VERSION " "
NS_ :

BS_:

BU_: ACU BDCM EPS BMS MCU VCU1 CDU TBOX EHB ESC Tester IHU PLG PTC EACP CLM ICU TAP ALM
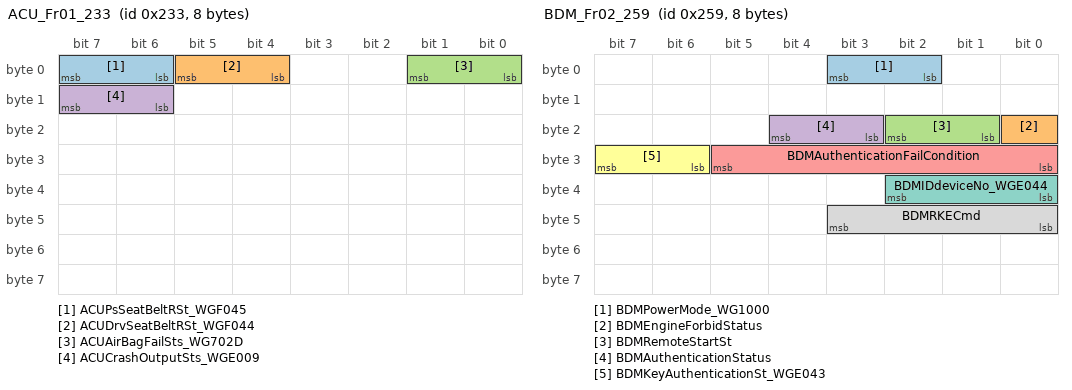
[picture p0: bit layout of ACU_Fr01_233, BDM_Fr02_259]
BO_ 563 ACU_Fr01_233: 8 ACU
 SG_ ACUPsSeatBeltRSt_WGF045 : 7|2@0+(1,0)[0|3] "" Vector__XXX
 SG_ ACUDrvSeatBeltRSt_WGF044 : 5|2@0+(1,0)[0|3] "" Vector__XXX
 SG_ ACUAirBagFailSts_WG702D : 1|2@0+(1,0)[0|3] "" Vector__XXX
 SG_ ACUCrashOutputSts_WGE009 : 15|2@0+(1,0)[0|3] "" Vector__XXX
BO_ 825 BDM_Fr01_339: 8 BDCM
 SG_ BDMAlarmMode_WG704C : 2|3@0+(1,0)[0|7] "" Vector__XXX
 SG_ BDMBackDoorAjar_WGC00E : 7|3@0+(1,0)[0|7] "" Vector__XXX
 SG_ BDMDriverDoorAjar_WGC00A : 9|2@0+(1,0)[0|3] "" Vector__XXX
 SG_ BDMPassDoorAjar_WGC00B : 11|2@0+(1,0)[0|3] "" Vector__XXX
 SG_ BDMRearDriverDoorAjar_WGC00C : 13|2@0+(1,0)[0|3] "" Vector__XXX
 SG_ BDMRearPassDoorAjar_WGC00D : 15|2@0+(1,0)[0|3] "" Vector__XXX
 SG_ BDMPositionLampSt_WGC003 : 16|1@0+(1,0)[0|1] "" Vector__XXX
 SG_ BDMBacklightStatus : 17|1@0+(1,0)[0|1] "" Vector__XXX
 SG_ BDMLowBeamSt_WGC009 : 18|1@0+(1,0)[0|1] "" Vector__XXX
 SG_ BDMLeftTurnLightSt_WGC006 : 19|1@0+(1,0)[0|1] "" Vector__XXX
 SG_ BDMRightTurnLightSt_WGC007 : 20|1@0+(1,0)[0|1] "" Vector__XXX
 SG_ BDMRearFogLampSt_WGC002 : 21|1@0+(1,0)[0|1] "" Vector__XXX
 SG_ BDMFrontFogLampSt : 22|1@0+(1,0)[0|1] "" Vector__XXX
 SG_ BDMDRLSt : 23|1@0+(1,0)[0|1] "" Vector__XXX
 SG_ BDMHighBeamSt_WGC008 : 24|1@0+(1,0)[0|1] "" Vector__XXX
 SG_ BDMHazardLampSt_WGF015 : 25|1@0+(1,0)[0|1] "" Vector__XXX
 SG_ BDMFrontWiperSt : 34|3@0+(1,0)[0|7] "" Vector__XXX
 SG_ BDMDoorLockSts_WGF000 : 38|1@0+(1,0)[0|1] "" Vector__XXX
 SG_ BDMRearDefrostSts : 39|1@0+(1,0)[0|1] "" Vector__XXX
 SG_ BDMTrunkLockSts_WGF004 : 43|1@0+(1,0)[0|1] "" Vector__XXX
BO_ 601 BDM_Fr02_259: 8 BDCM
 SG_ BDMPowerMode_WG1000 : 3|2@0+(1,0)[0|3] "" Vector__XXX
 SG_ BDMEngineForbidStatus : 16|1@0+(1,0)[0|1] "" Vector__XXX
 SG_ BDMRemoteStartSt : 18|2@0+(1,0)[0|3] "" Vector__XXX
 SG_ BDMAuthenticationStatus : 20|2@0+(1,0)[0|3] "" Vector__XXX
 SG_ BDMAuthenticationFailCondition : 29|6@0+(1,0)[0|63] "" Vector__XXX
 SG_ BDMKeyAuthenticationSt_WGE043 : 31|2@0+(1,0)[0|3] "" Vector__XXX
 SG_ BDMIDdeviceNo_WGE044 : 34|3@0+(1,0)[0|7] "" Vector__XXX
 SG_ BDMRKECmd : 43|4@0+(1,0)[0|15] "" Vector__XXX
BO_ 618 BDM_Fr03_26A: 8 BDCM
 SG_ BDMDoorHandleSensorFailureInd : 1|1@0+(1,0)[0|1] "" Vector__XXX
 SG_ BDMBrakeLightSts_WGF01B : 2|1@0+(1,0)[0|1] "" Vector__XXX
 SG_ BDMKeyNotFindIndication : 10|1@0+(1,0)[0|1] "" Vector__XXX
 SG_ BDMKeyLowBatteryIndication : 11|1@0+(1,0)[0|1] "" Vector__XXX
 SG_ BDMKeyInIndication : 12|1@0+(1,0)[0|1] "" Vector__XXX
 SG_ BDMDepressBrakePedalIndication : 14|1@0+(1,0)[0|1] "" Vector__XXX
 SG_ BDMShiftGearToPNIndication : 15|1@0+(1,0)[0|1] "" Vector__XXX
 SG_ BDMShiftGearToPIndication : 16|1@0+(1,0)[0|1] "" Vector__XXX
 SG_ BDMBackupStartIndication : 17|1@0+(1,0)[0|1] "" Vector__XXX
 SG_ RearFogLampFailedSts : 42|1@0+(1,0)[0|1] "" Vector__XXX
 SG_ SSBFailedSts : 45|1@0+(1,0)[0|1] "" Vector__XXX
 SG_ CHMSLFailedSts : 21|1@0+(1,0)[0|1] "" Vector__XXX
 SG_ StopLampFailedSts_WG7049 : 22|1@0+(1,0)[0|1] "" Vector__XXX
 SG_ SRMSunroofPosition : 34|3@0+(1,0)[0|7] "" Vector__XXX
 SG_ SRMSunshadePosition : 47|2@0+(1,0)[0|3] "" Vector__XXX
 SG_ DriverHeatingStatus : 50|3@0+(1,0)[0|7] "" Vector__XXX
 SG_ PassengerHeatingStatus : 53|3@0+(1,0)[0|7] "" Vector__XXX
 SG_ SHMLHFailure : 57|1@0+(1,0)[0|1] "" Vector__XXX
 SG_ SHMRHFailure : 56|1@0+(1,0)[0|1] "" Vector__XXX
BO_ 906 BDM_Fr04_38A: 8 BDCM
 SG_ BDMRtyreStatus : 0|1@0+(1,0)[0|1] "" Vector__XXX
 SG_ BDMRLTyreLearntSt : 1|1@0+(1,0)[0|1] "" Vector__XXX
 SG_ BDMRLTyrePressureWarn_WG500F : 3|2@0+(1,0)[0|3] "" Vector__XXX
 SG_ BDMRLTyreTemperatureWarn_WG5011 : 4|1@0+(1,0)[0|1] "" Vector__XXX
 SG_ BDMRLTyreQucikLeak : 5|1@0+(1,0)[0|1] "" Vector__XXX
 SG_ BDMRLTyreSensorFailure : 6|1@0+(1,0)[0|1] "" Vector__XXX
 SG_ BDMRLTyreLowBattery_WG5012 : 7|1@0+(1,0)[0|1] "" Vector__XXX
 SG_ BDMRLTyrePressure_WGF024 : 15|8@0+(1.373,100)[100|488.742] "" Vector__XXX
 SG_ BDMRLTyreTemperature_WGF023 : 23|8@0+(1,-60)[-60|194] "" Vector__XXX
 SG_ BDMRRTyreLearntSt : 25|1@0+(1,0)[0|1] "" Vector__XXX
 SG_ BDMRRTyrePressureWarn_WG5015 : 27|2@0+(1,0)[0|3] "" Vector__XXX
 SG_ BDMRRTyreTemperatureWarn_WG5017 : 28|1@0+(1,0)[0|1] "" Vector__XXX
 SG_ BDMRRTyreQucikLeak : 29|1@0+(1,0)[0|1] "" Vector__XXX
 SG_ BDMRRTyreSensorFailure : 30|1@0+(1,0)[0|1] "" Vector__XXX
 SG_ BDMRRTyreLowBattery_WG5018 : 31|1@0+(1,0)[0|1] "" Vector__XXX
 SG_ BDMRRTyrePressure_WGF022 : 39|8@0+(1.373,100)[100|488.742] "" Vector__XXX
 SG_ BDMRRTyreTemperature_WGF021 : 47|8@0+(1,-60)[-60|194] "" Vector__XXX
BO_ 874 BDM_Fr05_36A: 8 BDCM
 SG_ BDMFtyreStatus : 0|1@0+(1,0)[0|1] "" Vector__XXX
 SG_ BDMFLTyreLearntSt : 1|1@0+(1,0)[0|1] "" Vector__XXX
 SG_ BDMFLTyrePressureWarn_WG5003 : 3|2@0+(1,0)[0|3] "" Vector__XXX
 SG_ BDMFLTyreTemperatureWarn_WG5005 : 4|1@0+(1,0)[0|1] "" Vector__XXX
 SG_ BDMFLTyreQucikLeak : 5|1@0+(1,0)[0|1] "" Vector__XXX
 SG_ BDMFLTyreSensorFailure : 6|1@0+(1,0)[0|1] "" Vector__XXX
 SG_ BDMFLTyreLowBattery_WG5006 : 7|1@0+(1,0)[0|1] "" Vector__XXX
 SG_ BDMFLTyrePressure_WGF020 : 15|8@0+(1.373,100)[100|488.742] "" Vector__XXX
 SG_ BDMFLTyreTemperature_WGF01F : 23|8@0+(1,-60)[-60|194] "" Vector__XXX
 SG_ BDMFRTyreLearntSt : 25|1@0+(1,0)[0|1] "" Vector__XXX
 SG_ BDMFRTyrePressureWarn_WG5009 : 27|2@0+(1,0)[0|3] "" Vector__XXX
 SG_ BDMFRTyreTemperatureWarn_WG500B : 28|1@0+(1,0)[0|1] "" Vector__XXX
 SG_ BDMFRTyreQucikLeak : 29|1@0+(1,0)[0|1] "" Vector__XXX
 SG_ BDMFRTyreSensorFailure : 30|1@0+(1,0)[0|1] "" Vector__XXX
 SG_ BDMFRTyreLowBattery_WG500C : 31|1@0+(1,0)[0|1] "" Vector__XXX
 SG_ BDMFRTyrePressure_WGF01E : 39|8@0+(1.373,100)[100|488.742] "" Vector__XXX
 SG_ BDMFRTyreTemperature_WGF01D : 47|8@0+(1,-60)[-60|194] "" Vector__XXX
 SG_ BDMSystemFailure_WG704B : 55|2@0+(1,0)[0|3] "" Vector__XXX
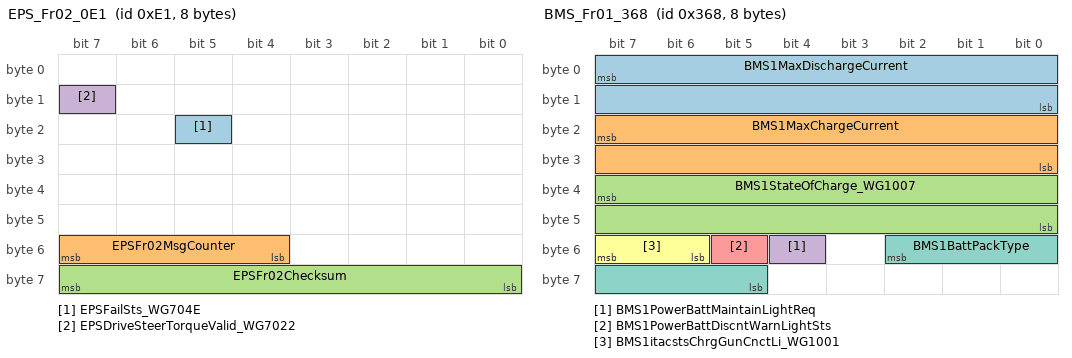
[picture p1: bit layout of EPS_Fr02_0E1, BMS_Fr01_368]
BO_ 225 EPS_Fr02_0E1: 8 EPS
 SG_ EPSFailSts_WG704E : 21|1@0+(1,0)[0|1] "" Vector__XXX
 SG_ EPSFr02MsgCounter : 55|4@0+(1,0)[0|15] "" Vector__XXX
 SG_ EPSFr02Checksum : 63|8@0+(1,0)[0|255] "" Vector__XXX
 SG_ EPSDriveSteerTorqueValid_WG7022 : 15|1@0+(1,0)[0|1] "" Vector__XXX
BO_ 481 EPS_Fr03_1E1: 8 EPS
 SG_ EPSSteeringAngleValid : 6|1@0+(1,0)[0|1] "" Vector__XXX
 SG_ EPSSteeringAngleSpd : 15|8@0+(4,0)[0|1020] "dgree/s" Vector__XXX
 SG_ EPSSteeringAngle_WGF03A : 23|16@0+(0.1,-720)[-720|720] "dgree" Vector__XXX
 SG_ EPSEleStrFailFlag_WG7021 : 3|2@0+(1,0)[0|3] "" Vector__XXX
BO_ 872 BMS_Fr01_368: 8 BMS
 SG_ BMS1MaxDischargeCurrent : 7|16@0+(0.05,-1600)[0|1024] "A" Vector__XXX
 SG_ BMS1MaxChargeCurrent : 23|16@0+(0.05,-1600)[0|1024] "A" Vector__XXX
 SG_ BMS1StateOfCharge_WG1007 : 39|16@0+(0.01,0)[0|100] "%" Vector__XXX
 SG_ BMS1PowerBattMaintainLightReq : 52|1@0+(1,0)[0|1] "" Vector__XXX
 SG_ BMS1PowerBattDiscntWarnLightSts : 53|1@0+(1,0)[0|1] "" Vector__XXX
 SG_ BMS1itacstsChrgGunCnctLi_WG1001 : 55|2@0+(1,0)[0|3] "" Vector__XXX
 SG_ BMS1BattPackType : 50|6@0+(1,0)[0|63] "" Vector__XXX
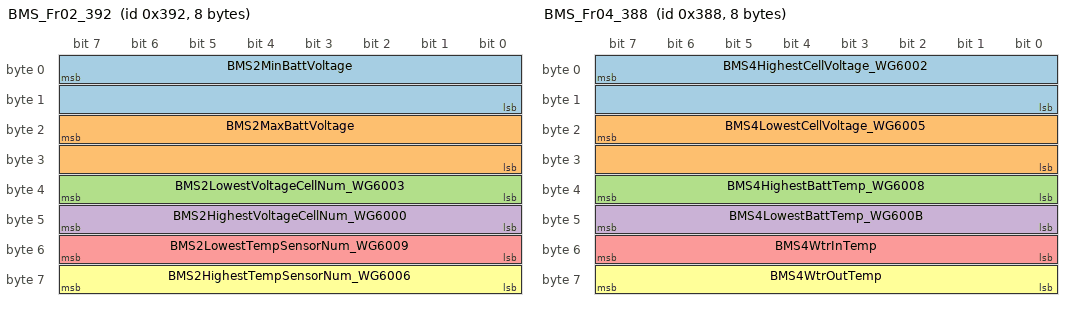
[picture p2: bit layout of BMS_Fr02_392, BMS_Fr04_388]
BO_ 914 BMS_Fr02_392: 8 BMS
 SG_ BMS2MinBattVoltage : 7|16@0+(0.05,0)[0|1000] "V" Vector__XXX
 SG_ BMS2MaxBattVoltage : 23|16@0+(0.05,0)[0|1000] "V" Vector__XXX
 SG_ BMS2LowestVoltageCellNum_WG6003 : 39|8@0+(1,0)[0|200] "" Vector__XXX
 SG_ BMS2HighestVoltageCellNum_WG6000 : 47|8@0+(1,0)[0|200] "" Vector__XXX
 SG_ BMS2LowestTempSensorNum_WG6009 : 55|8@0+(1,0)[0|200] "" Vector__XXX
 SG_ BMS2HighestTempSensorNum_WG6006 : 63|8@0+(1,0)[0|200] "" Vector__XXX
BO_ 858 BMS_Fr03_35A: 8 BMS
 SG_ BMS3BatteryCurrent_WG1006 : 7|16@0+(0.05,-1600)[-600|600] "A" Vector__XXX
 SG_ BMS3BatteryVoltage_WG1005 : 23|16@0+(0.05,0)[0|1000] "V" Vector__XXX
 SG_ BMS3AverageBattTemp : 55|8@0+(1,-40)[-40|125] "℃" Vector__XXX
 SG_ BMS3StateOfHealth : 63|8@0+(1,0)[0|100] "%" Vector__XXX
BO_ 904 BMS_Fr04_388: 8 BMS
 SG_ BMS4HighestCellVoltage_WG6002 : 7|16@0+(1,0)[0|5000] "mv" Vector__XXX
 SG_ BMS4LowestCellVoltage_WG6005 : 23|16@0+(1,0)[0|5000] "mv" Vector__XXX
 SG_ BMS4HighestBattTemp_WG6008 : 39|8@0+(1,-40)[-40|125] "℃" Vector__XXX
 SG_ BMS4LowestBattTemp_WG600B : 47|8@0+(1,-40)[-40|125] "℃" Vector__XXX
 SG_ BMS4WtrInTemp : 55|8@0+(1,-40)[-40|125] "℃" Vector__XXX
 SG_ BMS4WtrOutTemp : 63|8@0+(1,-40)[-40|125] "℃" Vector__XXX
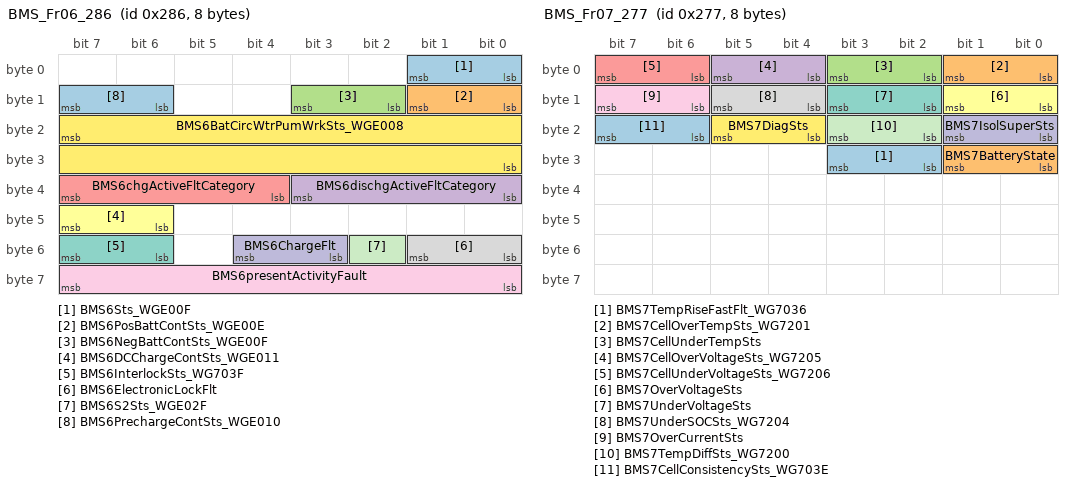
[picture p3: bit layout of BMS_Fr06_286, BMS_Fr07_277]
BO_ 646 BMS_Fr06_286: 8 BMS
 SG_ BMS6Sts_WGE00F : 1|2@0+(1,0)[0|3] "" Vector__XXX
 SG_ BMS6PosBattContSts_WGE00E : 9|2@0+(1,0)[0|3] "" Vector__XXX
 SG_ BMS6NegBattContSts_WGE00F : 11|2@0+(1,0)[0|3] "" Vector__XXX
 SG_ BMS6dischgActiveFltCategory : 35|4@0+(1,0)[0|15] "" Vector__XXX
 SG_ BMS6chgActiveFltCategory : 39|4@0+(1,0)[0|15] "" Vector__XXX
 SG_ BMS6DCChargeContSts_WGE011 : 47|2@0+(1,0)[0|3] "" Vector__XXX
 SG_ BMS6InterlockSts_WG703F : 55|2@0+(1,0)[0|3] "" Vector__XXX
 SG_ BMS6ElectronicLockFlt : 49|2@0+(1,0)[0|3] "" Vector__XXX
 SG_ BMS6presentActivityFault : 63|8@0+(1,0)[0|128] "" Vector__XXX
 SG_ BMS6ChargeFlt : 52|2@0+(1,0)[0|3] "" Vector__XXX
 SG_ BMS6S2Sts_WGE02F : 50|1@0+(1,0)[0|1] "" Vector__XXX
 SG_ BMS6BatCircWtrPumWrkSts_WGE008 : 23|16@0+(0.1,0)[0|100] "%" Vector__XXX
 SG_ BMS6PrechargeContSts_WGE010 : 15|2@0+(1,0)[0|3] "" Vector__XXX
BO_ 631 BMS_Fr07_277: 8 BMS
 SG_ BMS7TempRiseFastFlt_WG7036 : 27|2@0+(1,0)[0|3] "" Vector__XXX
 SG_ BMS7CellOverTempSts_WG7201 : 1|2@0+(1,0)[0|3] "" Vector__XXX
 SG_ BMS7CellUnderTempSts : 3|2@0+(1,0)[0|3] "" Vector__XXX
 SG_ BMS7CellOverVoltageSts_WG7205 : 5|2@0+(1,0)[0|3] "" Vector__XXX
 SG_ BMS7CellUnderVoltageSts_WG7206 : 7|2@0+(1,0)[0|3] "" Vector__XXX
 SG_ BMS7OverVoltageSts : 9|2@0+(1,0)[0|3] "" Vector__XXX
 SG_ BMS7UnderVoltageSts : 11|2@0+(1,0)[0|3] "" Vector__XXX
 SG_ BMS7UnderSOCSts_WG7204 : 13|2@0+(1,0)[0|3] "" Vector__XXX
 SG_ BMS7OverCurrentSts : 15|2@0+(1,0)[0|3] "" Vector__XXX
 SG_ BMS7IsolSuperSts : 17|2@0+(1,0)[0|3] "" Vector__XXX
 SG_ BMS7TempDiffSts_WG7200 : 19|2@0+(1,0)[0|3] "" Vector__XXX
 SG_ BMS7DiagSts : 21|2@0+(1,0)[0|3] "" Vector__XXX
 SG_ BMS7CellConsistencySts_WG703E : 23|2@0+(1,0)[0|3] "" Vector__XXX
 SG_ BMS7BatteryState : 25|2@0+(1,0)[0|3] "" Vector__XXX
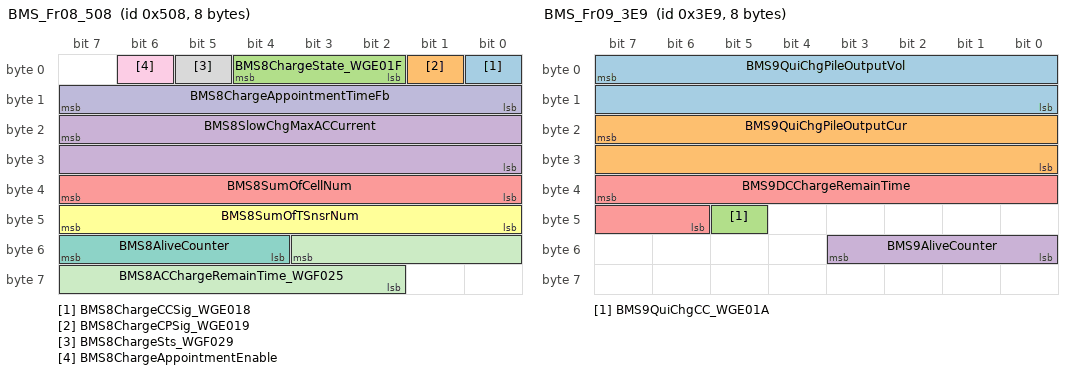
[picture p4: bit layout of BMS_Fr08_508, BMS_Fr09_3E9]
BO_ 1288 BMS_Fr08_508: 8 BMS
 SG_ BMS8ChargeCCSig_WGE018 : 0|1@0+(1,0)[0|1] "" Vector__XXX
 SG_ BMS8ChargeCPSig_WGE019 : 1|1@0+(1,0)[0|1] "" Vector__XXX
 SG_ BMS8ChargeState_WGE01F : 4|3@0+(1,0)[0|7] "" Vector__XXX
 SG_ BMS8SlowChgMaxACCurrent : 23|16@0+(0.05,-1600)[0|600] "A" Vector__XXX
 SG_ BMS8SumOfCellNum : 39|8@0+(1,0)[0|254] "" Vector__XXX
 SG_ BMS8SumOfTSnsrNum : 47|8@0+(1,0)[0|254] "" Vector__XXX
 SG_ BMS8AliveCounter : 55|4@0+(1,0)[0|15] "" Vector__XXX
 SG_ BMS8ChargeSts_WGF029 : 5|1@0+(1,0)[0|1] "" Vector__XXX
 SG_ BMS8ChargeAppointmentEnable : 6|1@0+(1,0)[0|1] "" Vector__XXX
 SG_ BMS8ChargeAppointmentTimeFb : 15|8@0+(10,0)[0|1440] "min" Vector__XXX
 SG_ BMS8ACChargeRemainTime_WGF025 : 51|10@0+(1,0)[0|1023] "min" Vector__XXX
BO_ 1001 BMS_Fr09_3E9: 8 BMS
 SG_ BMS9QuiChgPileOutputVol : 7|16@0+(0.05,0)[0|1000] "V" Vector__XXX
 SG_ BMS9QuiChgPileOutputCur : 23|16@0+(0.05,-1600)[0|600] "A" Vector__XXX
 SG_ BMS9QuiChgCC_WGE01A : 45|1@0+(1,0)[0|1] "" Vector__XXX
 SG_ BMS9AliveCounter : 51|4@0+(1,0)[0|15] "" Vector__XXX
 SG_ BMS9DCChargeRemainTime : 39|10@0+(1,0)[0|1023] "min" Vector__XXX
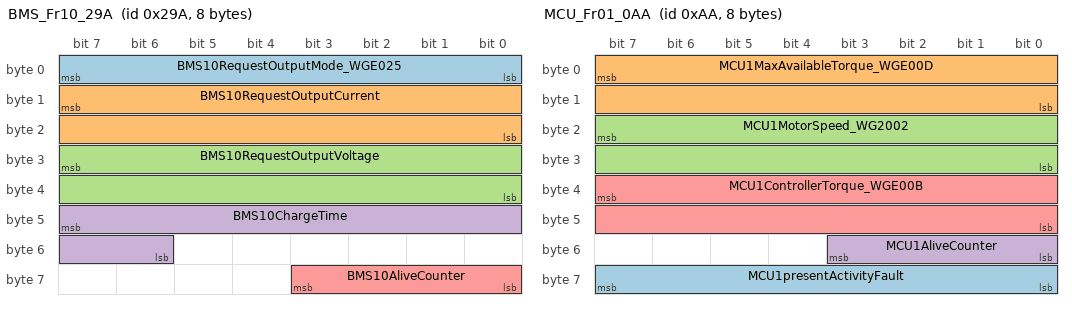
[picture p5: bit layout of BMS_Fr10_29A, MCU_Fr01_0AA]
BO_ 666 BMS_Fr10_29A: 8 BMS
 SG_ BMS10RequestOutputMode_WGE025 : 7|8@0+(1,0)[0|255] "" Vector__XXX
 SG_ BMS10RequestOutputCurrent : 15|16@0+(0.05,0)[0|400] "A" Vector__XXX
 SG_ BMS10RequestOutputVoltage : 31|16@0+(0.05,0)[0|1000] "V" Vector__XXX
 SG_ BMS10ChargeTime : 47|10@0+(1,0)[0|1023] "" Vector__XXX
 SG_ BMS10AliveCounter : 59|4@0+(1,0)[0|15] "" Vector__XXX
BO_ 1291 BMS_Fr11_50B: 8 BMS
 SG_ 单体电压号_WI1 : 7|8@0+(1,0)[0|255] "" Vector__XXX
 SG_ 单体电压1_WM1I1G8000 : 15|16@0+(1,0)[0|5000] "" Vector__XXX
 SG_ 温度探针号_WI2 : 55|8@0+(1,0)[0|255] "" Vector__XXX
 SG_ 温度探针1_WM1I2G9000 : 63|8@0+(1,-40)[-40|125] "" Vector__XXX
BO_ 170 MCU_Fr01_0AA: 8 MCU
 SG_ MCU1presentActivityFault : 63|8@0+(1,0)[0|128] "" Vector__XXX
 SG_ MCU1MaxAvailableTorque_WGE00D : 7|16@0+(0.05,0)[0|1024] "Nm" Vector__XXX
 SG_ MCU1MotorSpeed_WG2002 : 23|16@0+(0.5,-16000)[-16000|16000] "Rpm" Vector__XXX
 SG_ MCU1AliveCounter : 51|4@0+(1,0)[0|15] "" Vector__XXX
 SG_ MCU1ControllerTorque_WGE00B : 39|16@0+(0.05,-1024)[-1024|1024] "Nm" Vector__XXX
BO_ 187 MCU_Fr02_0BB: 8 MCU
 SG_ MCU2FaultLevel : 2|2@0+(1,0)[0|3] "" Vector__XXX
 SG_ MCU2MotorBlockWarning : 4|1@0+(1,0)[0|1] "" Vector__XXX
 SG_ MCU22OpenProtionLockFault_WG7038 : 5|1@0+(1,0)[0|1] "" Vector__XXX
 SG_ MCU2CoolingSystemFault : 6|1@0+(1,0)[0|1] "" Vector__XXX
 SG_ MCU2SelfcheckFault : 7|1@0+(1,0)[0|1] "" Vector__XXX
 SG_ MCU2SensorCheckFault : 12|1@0+(1,0)[0|1] "" Vector__XXX
 SG_ MCU2BatteryCheckFault_WG7025 : 13|1@0+(1,0)[0|1] "" Vector__XXX
 SG_ MCU2MotorLackofPhaseFault : 14|1@0+(1,0)[0|1] "" Vector__XXX
 SG_ MCU2RDCAlignmentFault : 15|1@0+(1,0)[0|1] "" Vector__XXX
 SG_ MCU2PhaseOvercurrentFault : 32|1@0+(1,0)[0|1] "" Vector__XXX
 SG_ MCU2InverterFault_WG7037 : 33|1@0+(1,0)[0|1] "" Vector__XXX
 SG_ MCU2SensorSupplyVoltageFault : 39|1@0+(1,0)[0|1] "" Vector__XXX
 SG_ MCU2DClinkOvercurrentFault : 40|1@0+(1,0)[0|1] "" Vector__XXX
 SG_ MCU2GateDriDesaturFault_WG7027 : 41|1@0+(1,0)[0|1] "" Vector__XXX
 SG_ MCU2MotorPosSensorFault_WG7028 : 42|1@0+(1,0)[0|1] "" Vector__XXX
 SG_ MCU22DischargeOverTime : 43|1@0+(1,0)[0|1] "" Vector__XXX
 SG_ MCU22SumPhaseCurrentOverThd : 44|1@0+(1,0)[0|1] "" Vector__XXX
 SG_ MCU2MotorOvertemperatureFault : 46|2@0+(1,0)[0|3] "" Vector__XXX
 SG_ MCU22AphaseOvercurrentWarning : 47|1@0+(1,0)[0|1] "" Vector__XXX
 SG_ MCU22BphaseOvercurrentWarning : 48|1@0+(1,0)[0|1] "" Vector__XXX
 SG_ MCU2CphaseOvercurrentWarning : 49|1@0+(1,0)[0|1] "" Vector__XXX
 SG_ MCU2InverterOvertempFault_WG720F : 51|2@0+(1,0)[0|3] "" Vector__XXX
 SG_ MCU2RxCANFailed_WG7044 : 52|1@0+(1,0)[0|1] "" Vector__XXX
 SG_ MCU2LVPowerSupplyFault : 53|1@0+(1,0)[0|1] "" Vector__XXX
 SG_ MCU2HVBatteryConnectstates : 55|1@0+(1,0)[0|1] "" Vector__XXX
 SG_ MCU2VCUInverterstates : 56|1@0+(1,0)[0|1] "" Vector__XXX
 SG_ MCU2SafetyFault : 57|1@0+(1,0)[0|1] "" Vector__XXX
 SG_ MCU2ModeError : 58|1@0+(1,0)[0|1] "" Vector__XXX
 SG_ MCU2GateDriverVoltageSupplyFault : 59|1@0+(1,0)[0|1] "" Vector__XXX
 SG_ MCU2Fr02AliveCounter : 63|4@0+(1,0)[0|15] "" Vector__XXX
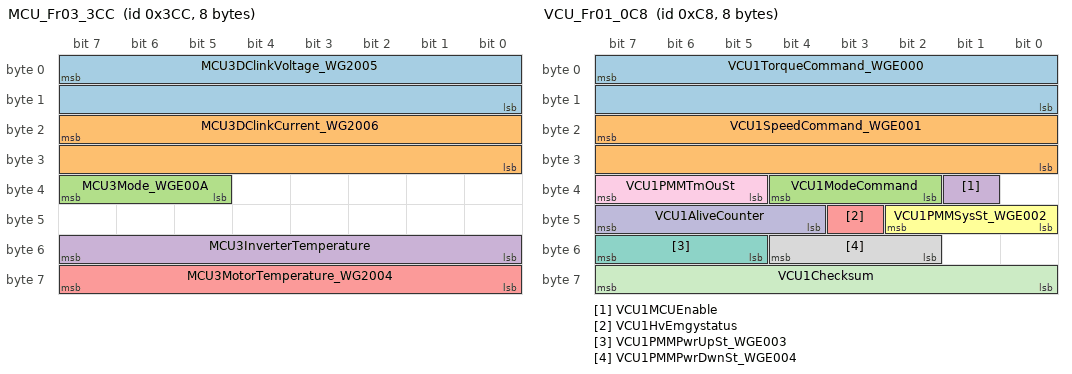
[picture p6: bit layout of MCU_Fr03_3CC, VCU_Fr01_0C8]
BO_ 972 MCU_Fr03_3CC: 8 MCU
 SG_ MCU3DClinkVoltage_WG2005 : 7|16@0+(0.05,0)[0|600] "V" Vector__XXX
 SG_ MCU3DClinkCurrent_WG2006 : 23|16@0+(0.05,-512)[-512|512] "A" Vector__XXX
 SG_ MCU3Mode_WGE00A : 39|3@0+(1,0)[0|7] "" Vector__XXX
 SG_ MCU3InverterTemperature : 55|8@0+(1,-48)[-48|206] "℃" Vector__XXX
 SG_ MCU3MotorTemperature_WG2004 : 63|8@0+(1,-48)[-48|206] "℃" Vector__XXX
BO_ 1072 MCU_Fr04_430: 8 MCU
 SG_ MCU4AlOfsNoPlaus : 0|1@0+(1,0)[0|1] "" Vector__XXX
 SG_ MCU4CanBusOff : 1|1@0+(1,0)[0|1] "" Vector__XXX
 SG_ MCU4EppPosMonShrGnd : 2|1@0+(1,0)[0|1] "" Vector__XXX
 SG_ MCU4EppPosShrGnd : 3|1@0+(1,0)[0|1] "" Vector__XXX
 SG_ MCU4IUMonOvHiRng : 4|1@0+(1,0)[0|1] "" Vector__XXX
 SG_ MCU4IUMonOvLoRng : 5|1@0+(1,0)[0|1] "" Vector__XXX
 SG_ MCU4IUOc : 6|1@0+(1,0)[0|1] "" Vector__XXX
 SG_ MCU4IUOvHiRng : 7|1@0+(1,0)[0|1] "" Vector__XXX
 SG_ MCU4IUOvLoRng : 8|1@0+(1,0)[0|1] "" Vector__XXX
 SG_ MCU4IVMonOvHiRng : 9|1@0+(1,0)[0|1] "" Vector__XXX
 SG_ MCU4IVMonOvLoRng : 10|1@0+(1,0)[0|1] "" Vector__XXX
 SG_ MCU4IVOc_WG7023 : 11|1@0+(1,0)[0|1] "" Vector__XXX
 SG_ MCU4IVOvHiRng : 12|1@0+(1,0)[0|1] "" Vector__XXX
 SG_ MCU4IVOvLoRng : 13|1@0+(1,0)[0|1] "" Vector__XXX
 SG_ MCU4IWMonOvHiRng : 14|1@0+(1,0)[0|1] "" Vector__XXX
 SG_ MCU4IWMonOvLoRng : 15|1@0+(1,0)[0|1] "" Vector__XXX
 SG_ MCU4IWOc_WG7024 : 16|1@0+(1,0)[0|1] "" Vector__XXX
 SG_ MCU4IWOvHiRng : 17|1@0+(1,0)[0|1] "" Vector__XXX
 SG_ MCU4IWOvLoRng : 18|1@0+(1,0)[0|1] "" Vector__XXX
 SG_ MCU4IphaOC_WG7029 : 19|1@0+(1,0)[0|1] "" Vector__XXX
 SG_ MCU4IphaOffCal : 20|1@0+(1,0)[0|1] "" Vector__XXX
 SG_ MCU4MosTHiRng : 21|1@0+(1,0)[0|1] "" Vector__XXX
 SG_ MCU4NFltHA : 22|1@0+(1,0)[0|1] "" Vector__XXX
 SG_ MCU4NFltHB : 23|1@0+(1,0)[0|1] "" Vector__XXX
 SG_ MCU4NFltLA : 24|1@0+(1,0)[0|1] "" Vector__XXX
 SG_ MCU4NFltLB : 25|1@0+(1,0)[0|1] "" Vector__XXX
 SG_ MCU4RslvDos : 26|1@0+(1,0)[0|1] "" Vector__XXX
 SG_ MCU4RslvLos : 27|1@0+(1,0)[0|1] "" Vector__XXX
 SG_ MCU4RslvLot : 28|1@0+(1,0)[0|1] "" Vector__XXX
 SG_ MCU4StallmotRng : 29|1@0+(1,0)[0|1] "" Vector__XXX
 SG_ MCU4HwPhaCurPosBackErr : 30|1@0+(1,0)[0|1] "" Vector__XXX
 SG_ MCU4HwPhaCurNegBackErr : 31|1@0+(1,0)[0|1] "" Vector__XXX
 SG_ MCU4TimeovRng : 32|1@0+(1,0)[0|1] "" Vector__XXX
 SG_ MCU4TSttr1OvHiLim : 33|1@0+(1,0)[0|1] "" Vector__XXX
 SG_ MCU4TSttr1OvLoLim : 34|1@0+(1,0)[0|1] "" Vector__XXX
 SG_ MCU4TSttr2OvHiLim : 35|1@0+(1,0)[0|1] "" Vector__XXX
 SG_ MCU4TSttr2OvLoLim : 36|1@0+(1,0)[0|1] "" Vector__XXX
 SG_ MCU4TUErrOff : 37|1@0+(1,0)[0|1] "" Vector__XXX
 SG_ MCU4TVErrOff : 38|1@0+(1,0)[0|1] "" Vector__XXX
 SG_ MCU4TWErrOff : 39|1@0+(1,0)[0|1] "" Vector__XXX
 SG_ MCU4tDBCTempUHiLom : 40|1@0+(1,0)[0|1] "" Vector__XXX
 SG_ MCU4tDBCTempULoLom : 41|1@0+(1,0)[0|1] "" Vector__XXX
 SG_ MCU4tDBCTempVHiLom : 42|1@0+(1,0)[0|1] "" Vector__XXX
 SG_ MCU4tDBCTempVLoLom : 43|1@0+(1,0)[0|1] "" Vector__XXX
 SG_ MCU4tDBCTempWHiLom : 44|1@0+(1,0)[0|1] "" Vector__XXX
 SG_ MCU4tDBCTempWLoLom : 45|1@0+(1,0)[0|1] "" Vector__XXX
 SG_ MCU4QtShrGnd : 46|1@0+(1,0)[0|1] "" Vector__XXX
 SG_ MCU4SttrTemp1ShrGnd : 47|1@0+(1,0)[0|1] "" Vector__XXX
 SG_ MCU4SttrTemp2ShrGnd : 48|1@0+(1,0)[0|1] "" Vector__XXX
 SG_ MCU4UMonShrGnd : 49|1@0+(1,0)[0|1] "" Vector__XXX
 SG_ MCU4VMonShrGnd : 50|1@0+(1,0)[0|1] "" Vector__XXX
 SG_ MCU4WMonShrGnd : 51|1@0+(1,0)[0|1] "" Vector__XXX
 SG_ MCU4UShrGnd : 52|1@0+(1,0)[0|1] "" Vector__XXX
 SG_ MCU4VShrGnd : 53|1@0+(1,0)[0|1] "" Vector__XXX
 SG_ MCU4WShrGnd : 54|1@0+(1,0)[0|1] "" Vector__XXX
 SG_ MCU4UKl30Ov : 55|1@0+(1,0)[0|1] "" Vector__XXX
 SG_ MCU4UKl30Unv_WG7039 : 56|1@0+(1,0)[0|1] "" Vector__XXX
 SG_ MCU4VcuRecOvTime : 57|1@0+(1,0)[0|1] "" Vector__XXX
 SG_ MCU4UdcLnkOvHiRng_WG702A : 59|2@0+(1,0)[0|3] "" Vector__XXX
 SG_ MCU4UdcLnkOvLoRng_WG702B : 61|2@0+(1,0)[0|3] "" Vector__XXX
 SG_ MCU4OverSpdDetn : 63|2@0+(1,0)[0|3] "" Vector__XXX
BO_ 200 VCU_Fr01_0C8: 8 VCU1
 SG_ VCU1TorqueCommand_WGE000 : 7|16@0+(0.05,-1024)[-1024|1024] "Nm" Vector__XXX
 SG_ VCU1SpeedCommand_WGE001 : 23|16@0+(0.5,-16000)[-16000|16000] "RPM" Vector__XXX
 SG_ VCU1ModeCommand : 36|3@0+(1,0)[0|7] "" Vector__XXX
 SG_ VCU1MCUEnable : 33|1@0+(1,0)[0|1] "" Vector__XXX
 SG_ VCU1HvEmgystatus : 43|1@0+(1,0)[0|1] "" Vector__XXX
 SG_ VCU1PMMSysSt_WGE002 : 42|3@0+(1,0)[0|7] "" Vector__XXX
 SG_ VCU1PMMPwrUpSt_WGE003 : 55|3@0+(1,0)[0|7] "" Vector__XXX
 SG_ VCU1PMMPwrDwnSt_WGE004 : 52|3@0+(1,0)[0|7] "" Vector__XXX
 SG_ VCU1PMMTmOuSt : 39|3@0+(1,0)[0|7] "" Vector__XXX
 SG_ VCU1AliveCounter : 47|4@0+(1,0)[0|15] "" Vector__XXX
 SG_ VCU1Checksum : 63|8@0+(1,0)[0|255] "" Vector__XXX
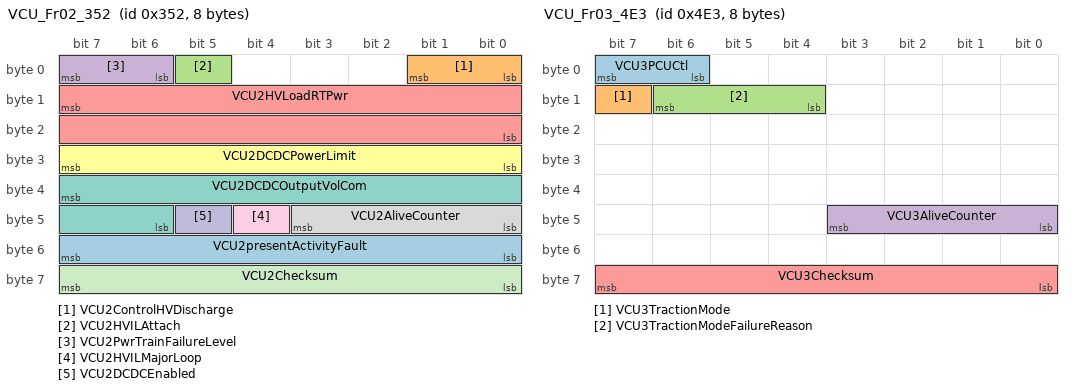
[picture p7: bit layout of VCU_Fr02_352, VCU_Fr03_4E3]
BO_ 850 VCU_Fr02_352: 8 VCU1
 SG_ VCU2presentActivityFault : 55|8@0+(1,0)[0|128] "" Vector__XXX
 SG_ VCU2ControlHVDischarge : 1|2@0+(1,0)[0|3] "" Vector__XXX
 SG_ VCU2HVILAttach : 5|1@0+(1,0)[0|1] "" Vector__XXX
 SG_ VCU2PwrTrainFailureLevel : 7|2@0+(1,0)[0|3] "" Vector__XXX
 SG_ VCU2HVLoadRTPwr : 15|16@0+(1,0)[0|65534] "w" Vector__XXX
 SG_ VCU2DCDCPowerLimit : 31|8@0+(0.01,0)[0|2.54] "Kw" Vector__XXX
 SG_ VCU2DCDCOutputVolCom : 39|10@0+(0.05,0)[0|51.15] "V" Vector__XXX
 SG_ VCU2AliveCounter : 43|4@0+(1,0)[0|15] "" Vector__XXX
 SG_ VCU2HVILMajorLoop : 44|1@0+(1,0)[0|1] "" Vector__XXX
 SG_ VCU2DCDCEnabled : 45|1@0+(1,0)[0|1] "" Vector__XXX
 SG_ VCU2Checksum : 63|8@0+(1,0)[0|255] "" Vector__XXX
BO_ 1251 VCU_Fr03_4E3: 8 VCU1
 SG_ VCU3PCUCtl : 7|2@0+(1,0)[0|3] "" Vector__XXX
 SG_ VCU3TractionMode : 15|1@0+(1,0)[0|1] "" Vector__XXX
 SG_ VCU3TractionModeFailureReason : 14|3@0+(1,0)[0|7] "" Vector__XXX
 SG_ VCU3AliveCounter : 43|4@0+(1,0)[0|15] "" Vector__XXX
 SG_ VCU3Checksum : 63|8@0+(1,0)[0|255] "" Vector__XXX
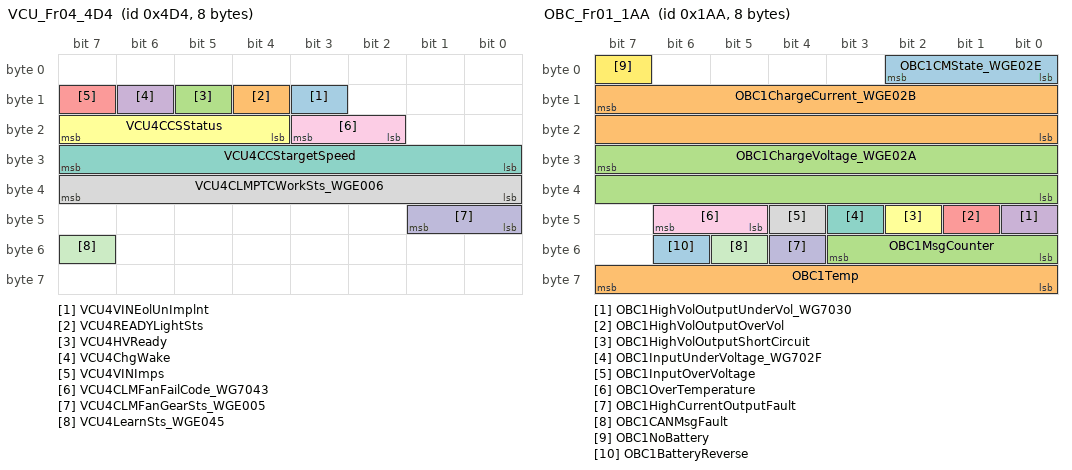
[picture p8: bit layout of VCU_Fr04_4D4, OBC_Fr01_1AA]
BO_ 1236 VCU_Fr04_4D4: 8 VCU1
 SG_ VCU4VINEolUnImplnt : 11|1@0+(1,0)[0|1] "" Vector__XXX
 SG_ VCU4READYLightSts : 12|1@0+(1,0)[0|1] "" Vector__XXX
 SG_ VCU4HVReady : 13|1@0+(1,0)[0|1] "" Vector__XXX
 SG_ VCU4ChgWake : 14|1@0+(1,0)[0|1] "" Vector__XXX
 SG_ VCU4VINImps : 15|1@0+(1,0)[0|1] "" Vector__XXX
 SG_ VCU4CCSStatus : 23|4@0+(1,0)[0|15] "" Vector__XXX
 SG_ VCU4CCStargetSpeed : 31|8@0+(1,0)[0|255] "Km/h" Vector__XXX
 SG_ VCU4CLMPTCWorkSts_WGE006 : 39|8@0+(1,0)[0|100] "%" Vector__XXX
 SG_ VCU4CLMFanFailCode_WG7043 : 19|2@0+(1,0)[0|3] "" Vector__XXX
 SG_ VCU4CLMFanGearSts_WGE005 : 41|2@0+(1,0)[0|3] "" Vector__XXX
 SG_ VCU4LearnSts_WGE045 : 55|1@0+(1,0)[0|1] "" Vector__XXX
BO_ 426 OBC_Fr01_1AA: 8 CDU
 SG_ OBC1CMState_WGE02E : 2|3@0+(1,0)[0|7] "" Vector__XXX
 SG_ OBC1ChargeCurrent_WGE02B : 15|16@0+(0.05,0)[0|400] "A" Vector__XXX
 SG_ OBC1ChargeVoltage_WGE02A : 31|16@0+(0.05,0)[0|1000] "V" Vector__XXX
 SG_ OBC1HighVolOutputUnderVol_WG7030 : 40|1@0+(1,0)[0|1] "" Vector__XXX
 SG_ OBC1HighVolOutputOverVol : 41|1@0+(1,0)[0|1] "" Vector__XXX
 SG_ OBC1HighVolOutputShortCircuit : 42|1@0+(1,0)[0|1] "" Vector__XXX
 SG_ OBC1InputUnderVoltage_WG702F : 43|1@0+(1,0)[0|1] "" Vector__XXX
 SG_ OBC1InputOverVoltage : 44|1@0+(1,0)[0|1] "" Vector__XXX
 SG_ OBC1OverTemperature : 46|2@0+(1,0)[0|3] "" Vector__XXX
 SG_ OBC1HighCurrentOutputFault : 52|1@0+(1,0)[0|1] "" Vector__XXX
 SG_ OBC1CANMsgFault : 53|1@0+(1,0)[0|1] "" Vector__XXX
 SG_ OBC1NoBattery : 7|1@0+(1,0)[0|1] "" Vector__XXX
 SG_ OBC1BatteryReverse : 54|1@0+(1,0)[0|1] "" Vector__XXX
 SG_ OBC1Temp : 63|8@0+(1,-48)[-48|206] "℃" Vector__XXX
 SG_ OBC1MsgCounter : 51|4@0+(1,0)[0|15] "" Vector__XXX
BO_ 487 OBC_Fr02_1E7: 8 CDU
 SG_ OBC2presentActivityFault : 63|8@0+(1,0)[0|128] "" Vector__XXX
 SG_ OBC2CurrentEnabPwrOutMax_WGE029 : 7|12@0+(0.005,0)[0|20.47] "KW" Vector__XXX
 SG_ OBC2FeedbackACPowerGridVolt : 31|16@0+(0.01,0)[0|655.34] "V" Vector__XXX
 SG_ OBC2FeedbackACPowerGridCur : 10|9@0+(0.1,0)[0|40] "A" Vector__XXX
BO_ 1433 OBC_Fr03_599: 8 CDU
 SG_ OBC3ChargeCurrentInp_WGE02C : 7|16@0+(0.05,0)[0|400] "A" Vector__XXX
 SG_ OBC3ChargeVoltageInp_WGE02D : 23|16@0+(0.05,0)[0|1000] "V" Vector__XXX
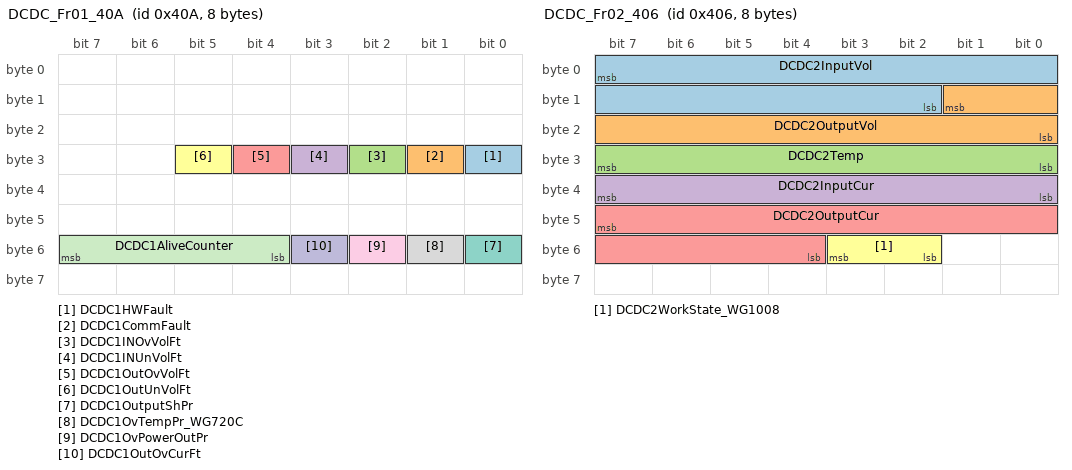
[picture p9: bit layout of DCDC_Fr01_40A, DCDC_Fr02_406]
BO_ 1034 DCDC_Fr01_40A: 8 CDU
 SG_ DCDC1HWFault : 24|1@0+(1,0)[0|1] "" Vector__XXX
 SG_ DCDC1CommFault : 25|1@0+(1,0)[0|1] "" Vector__XXX
 SG_ DCDC1INOvVolFt : 26|1@0+(1,0)[0|1] "" Vector__XXX
 SG_ DCDC1INUnVolFt : 27|1@0+(1,0)[0|1] "" Vector__XXX
 SG_ DCDC1OutOvVolFt : 28|1@0+(1,0)[0|1] "" Vector__XXX
 SG_ DCDC1OutUnVolFt : 29|1@0+(1,0)[0|1] "" Vector__XXX
 SG_ DCDC1OutputShPr : 48|1@0+(1,0)[0|1] "" Vector__XXX
 SG_ DCDC1OvTempPr_WG720C : 49|1@0+(1,0)[0|1] "" Vector__XXX
 SG_ DCDC1OvPowerOutPr : 50|1@0+(1,0)[0|1] "" Vector__XXX
 SG_ DCDC1OutOvCurFt : 51|1@0+(1,0)[0|1] "" Vector__XXX
 SG_ DCDC1AliveCounter : 55|4@0+(1,0)[0|15] "" Vector__XXX
BO_ 1030 DCDC_Fr02_406: 8 CDU
 SG_ DCDC2InputVol : 7|14@0+(0.05,0)[0|819.1] "V" Vector__XXX
 SG_ DCDC2OutputVol : 9|10@0+(0.05,0)[0|51.15] "V" Vector__XXX
 SG_ DCDC2Temp : 31|8@0+(1,-48)[-48|206] "℃" Vector__XXX
 SG_ DCDC2InputCur : 39|8@0+(0.1,0)[0|25.4] "A" Vector__XXX
 SG_ DCDC2OutputCur : 47|12@0+(0.05,0)[0|204.7] "A" Vector__XXX
 SG_ DCDC2WorkState_WG1008 : 51|2@0+(1,0)[0|3] "" Vector__XXX
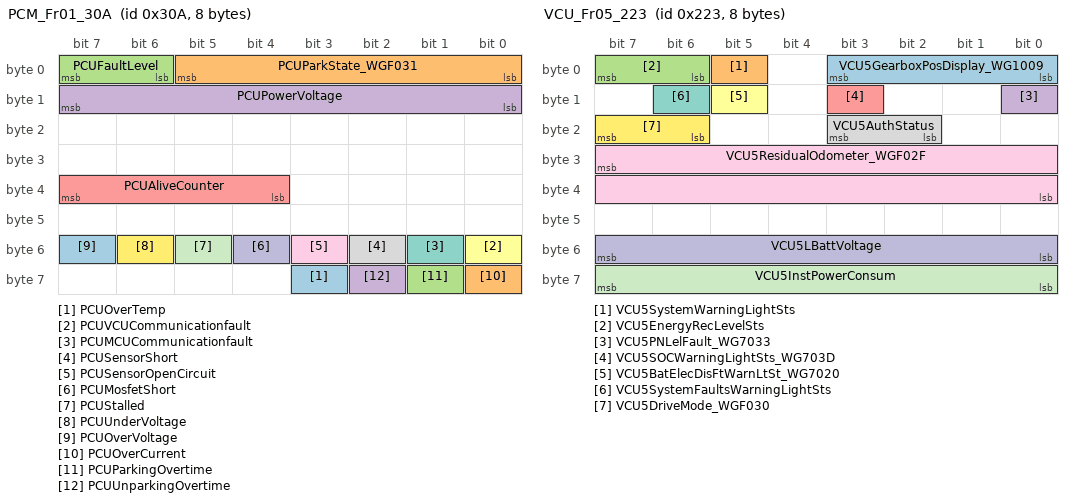
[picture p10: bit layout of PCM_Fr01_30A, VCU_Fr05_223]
BO_ 778 PCM_Fr01_30A: 8 MCU
 SG_ PCUOverTemp : 59|1@0+(1,0)[0|1] "" Vector__XXX
 SG_ PCUParkState_WGF031 : 5|6@0+(1,0)[0|63] "" Vector__XXX
 SG_ PCUFaultLevel : 7|2@0+(1,0)[0|3] "" Vector__XXX
 SG_ PCUPowerVoltage : 15|8@0+(1,0)[0|60] "V" Vector__XXX
 SG_ PCUAliveCounter : 39|4@0+(1,0)[0|15] "" Vector__XXX
 SG_ PCUVCUCommunicationfault : 48|1@0+(1,0)[0|1] "" Vector__XXX
 SG_ PCUMCUCommunicationfault : 49|1@0+(1,0)[0|1] "" Vector__XXX
 SG_ PCUSensorShort : 50|1@0+(1,0)[0|1] "" Vector__XXX
 SG_ PCUSensorOpenCircuit : 51|1@0+(1,0)[0|1] "" Vector__XXX
 SG_ PCUMosfetShort : 52|1@0+(1,0)[0|1] "" Vector__XXX
 SG_ PCUStalled : 53|1@0+(1,0)[0|1] "" Vector__XXX
 SG_ PCUUnderVoltage : 54|1@0+(1,0)[0|1] "" Vector__XXX
 SG_ PCUOverVoltage : 55|1@0+(1,0)[0|1] "" Vector__XXX
 SG_ PCUOverCurrent : 56|1@0+(1,0)[0|1] "" Vector__XXX
 SG_ PCUParkingOvertime : 57|1@0+(1,0)[0|1] "" Vector__XXX
 SG_ PCUUnparkingOvertime : 58|1@0+(1,0)[0|1] "" Vector__XXX
BO_ 547 VCU_Fr05_223: 8 VCU1
 SG_ VCU5GearboxPosDisplay_WG1009 : 3|4@0+(1,0)[0|15] "" Vector__XXX
 SG_ VCU5SystemWarningLightSts : 5|1@0+(1,0)[0|1] "" Vector__XXX
 SG_ VCU5EnergyRecLevelSts : 7|2@0+(1,0)[0|3] "" Vector__XXX
 SG_ VCU5PNLelFault_WG7033 : 8|1@0+(1,0)[0|1] "" Vector__XXX
 SG_ VCU5SOCWarningLightSts_WG703D : 11|1@0+(1,0)[0|1] "" Vector__XXX
 SG_ VCU5BatElecDisFtWarnLtSt_WG7020 : 13|1@0+(1,0)[0|1] "" Vector__XXX
 SG_ VCU5SystemFaultsWarningLightSts : 14|1@0+(1,0)[0|1] "" Vector__XXX
 SG_ VCU5AuthStatus : 19|2@0+(1,0)[0|3] "" Vector__XXX
 SG_ VCU5ResidualOdometer_WGF02F : 31|16@0+(1,0)[0|1024] "Km" Vector__XXX
 SG_ VCU5LBattVoltage : 55|8@0+(0.1,0)[0|18] "V" Vector__XXX
 SG_ VCU5InstPowerConsum : 63|8@0+(0.1,0)[0|25] "KW/h" Vector__XXX
 SG_ VCU5DriveMode_WGF030 : 23|2@0+(1,0)[0|3] "" Vector__XXX
BO_ 1067 VCU_Fr06_42B: 8 VCU1
 SG_ VCU6GasPedalPosition_WG100B : 15|8@0+(1,0)[0|100] "%" Vector__XXX
 SG_ VCU6GasPedalVolNo1 : 23|8@0+(0.1,0)[0|22.5] "v" Vector__XXX
 SG_ VCU6GasPedalVolNo2 : 31|8@0+(0.1,0)[0|22.5] "v" Vector__XXX
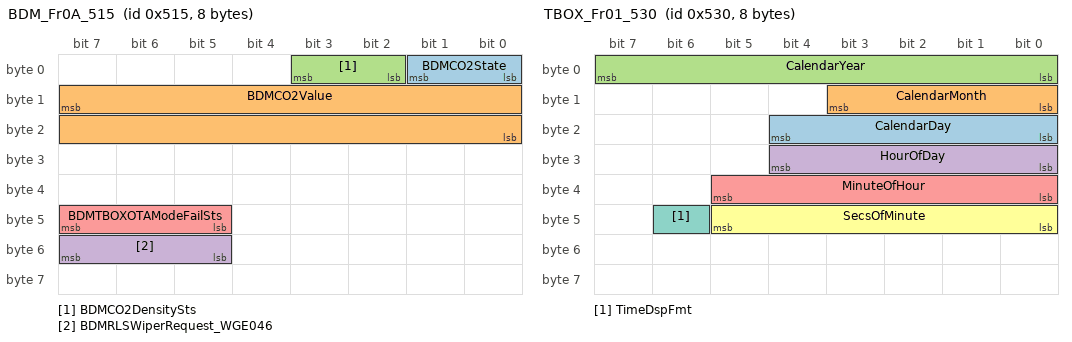
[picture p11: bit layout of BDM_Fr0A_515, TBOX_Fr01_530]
BO_ 1301 BDM_Fr0A_515: 8 BDCM
 SG_ BDMCO2State : 1|2@0+(1,0)[0|3] "" Vector__XXX
 SG_ BDMCO2Value : 15|16@0+(1,0)[0|5000] "ug/m3" Vector__XXX
 SG_ BDMCO2DensitySts : 3|2@0+(1,0)[0|3] "" Vector__XXX
 SG_ BDMRLSWiperRequest_WGE046 : 55|3@0+(1,0)[0|7] "" Vector__XXX
 SG_ BDMTBOXOTAModeFailSts : 47|3@0+(1,0)[0|7] "" Vector__XXX
BO_ 1328 TBOX_Fr01_530: 8 TBOX
 SG_ CalendarDay : 20|5@0+(1,0)[0|31] "days" Vector__XXX
 SG_ CalendarMonth : 11|4@0+(1,0)[0|15] "" Vector__XXX
 SG_ CalendarYear : 7|8@0+(1,2000)[2000|2255] "year" Vector__XXX
 SG_ HourOfDay : 28|5@0+(1,0)[0|23] "" Vector__XXX
 SG_ MinuteOfHour : 37|6@0+(1,0)[0|59] "" Vector__XXX
 SG_ SecsOfMinute : 45|6@0+(1,0)[0|59] "" Vector__XXX
 SG_ TimeDspFmt : 46|1@0+(1,0)[0|1] "" Vector__XXX
BO_ 1088 TBOX_Fr03_440: 8 TBOX
 SG_ TBOXRemoteStartReq : 0|1@0+(1,0)[0|1] "" Vector__XXX
 SG_ TBOXRemoteShutdownReq : 1|1@0+(1,0)[0|1] "" Vector__XXX
 SG_ TBOXStartForbidReq : 31|2@0+(1,0)[0|3] "" Vector__XXX
 SG_ TBOXChargeCmd : 3|1@0+(1,0)[0|1] "" Vector__XXX
 SG_ TBOXChargeAppointmentSet : 4|1@0+(1,0)[0|1] "" Vector__XXX
 SG_ TBOXChargeAppointmentTimeSet : 15|8@0+(10,0)[0|1440] "min" Vector__XXX
 SG_ TBOXRemoteLockCtrl : 17|2@0+(1,0)[0|3] "" Vector__XXX
 SG_ TBOXRemoteTrunkCtrl : 19|2@0+(1,0)[0|3] "" Vector__XXX
 SG_ TBOXFLWindowsCtrl : 7|3@0+(1,0)[0|7] "" Vector__XXX
 SG_ TBOXFRWindowsCtrl : 22|3@0+(1,0)[0|7] "" Vector__XXX
 SG_ TBOXRLWindowsCtrl : 26|3@0+(1,0)[0|7] "" Vector__XXX
 SG_ TBOXRRWindowsCtrl : 29|3@0+(1,0)[0|7] "" Vector__XXX
 SG_ TBOXRemoteSunroofCtrl : 47|3@0+(1,0)[0|7] "" Vector__XXX
 SG_ TBOXRemoteSunshadeCtrl : 33|2@0+(1,0)[0|3] "" Vector__XXX
 SG_ TBOXDVRRemotePhotoCtrl : 34|1@0+(1,0)[0|1] "" Vector__XXX
 SG_ TBOXDVRRemoteRecordCtrl : 35|1@0+(1,0)[0|1] "" Vector__XXX
 SG_ TBOXIRSRemotePhotoCtrl : 36|1@0+(1,0)[0|1] "" Vector__XXX
 SG_ TBOXIRSRemoteRecordCtrl : 37|1@0+(1,0)[0|1] "" Vector__XXX
 SG_ TBOXBDMOTAModeReq : 39|2@0+(1,0)[0|3] "" Vector__XXX
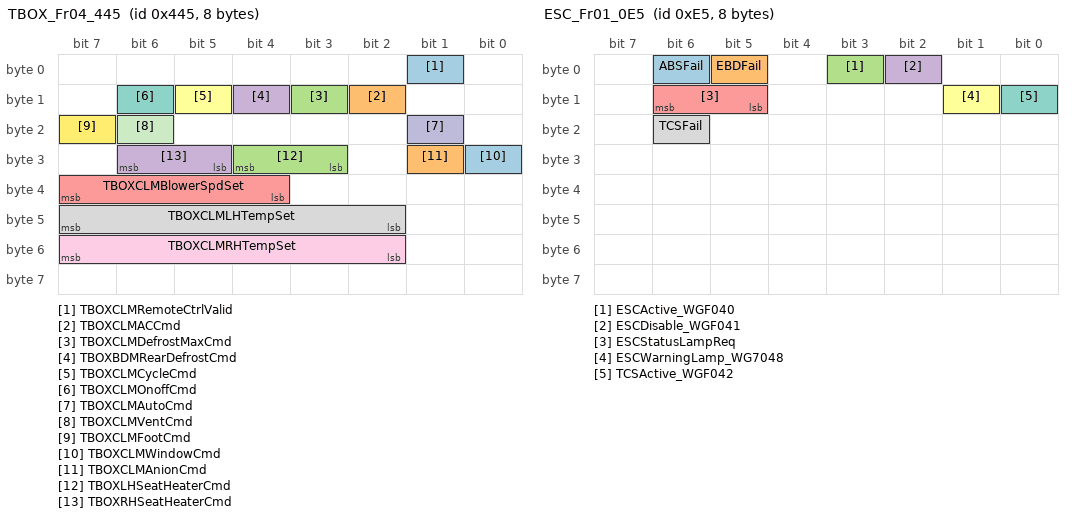
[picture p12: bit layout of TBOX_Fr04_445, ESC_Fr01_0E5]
BO_ 1093 TBOX_Fr04_445: 8 TBOX
 SG_ TBOXCLMRemoteCtrlValid : 1|1@0+(1,0)[0|1] "" Vector__XXX
 SG_ TBOXCLMACCmd : 10|1@0+(1,0)[0|1] "" Vector__XXX
 SG_ TBOXCLMDefrostMaxCmd : 11|1@0+(1,0)[0|1] "" Vector__XXX
 SG_ TBOXBDMRearDefrostCmd : 12|1@0+(1,0)[0|1] "" Vector__XXX
 SG_ TBOXCLMBlowerSpdSet : 39|4@0+(1,0)[0|15] "" Vector__XXX
 SG_ TBOXCLMCycleCmd : 13|1@0+(1,0)[0|1] "" Vector__XXX
 SG_ TBOXCLMOnoffCmd : 14|1@0+(1,0)[0|1] "" Vector__XXX
 SG_ TBOXCLMLHTempSet : 47|6@0+(0.5,16)[16|32] "" Vector__XXX
 SG_ TBOXCLMRHTempSet : 55|6@0+(0.5,16)[16|32] "" Vector__XXX
 SG_ TBOXCLMAutoCmd : 17|1@0+(1,0)[0|1] "" Vector__XXX
 SG_ TBOXCLMVentCmd : 22|1@0+(1,0)[0|1] "" Vector__XXX
 SG_ TBOXCLMFootCmd : 23|1@0+(1,0)[0|1] "" Vector__XXX
 SG_ TBOXCLMWindowCmd : 24|1@0+(1,0)[0|1] "" Vector__XXX
 SG_ TBOXCLMAnionCmd : 25|1@0+(1,0)[0|1] "" Vector__XXX
 SG_ TBOXLHSeatHeaterCmd : 28|2@0+(1,0)[0|3] "" Vector__XXX
 SG_ TBOXRHSeatHeaterCmd : 30|2@0+(1,0)[0|3] "" Vector__XXX
BO_ 454 EHB_Fr01_1C6: 8 EHB
 SG_ BrakePedalApplied_WG100C : 23|1@0+(1,0)[0|1] "" Vector__XXX
 SG_ BrakePedalAppliedV : 5|1@0+(1,0)[0|1] "" Vector__XXX
BO_ 456 EHB_Fr02_1C8: 8 EHB
 SG_ BrakPedalDisp : 31|16@0+(0.0078125,0)[0|200] "mm" Vector__XXX
 SG_ BrakPedalDispQ : 1|1@0+(1,0)[0|1] "" Vector__XXX
 SG_ EHBFr02MsgCounter : 55|4@0+(1,0)[0|15] "" Vector__XXX
 SG_ EHBFr02Checksum : 63|8@0+(1,0)[0|255] "" Vector__XXX
BO_ 229 ESC_Fr01_0E5: 8 ESC
 SG_ ABSFail : 6|1@0+(1,0)[0|1] "" Vector__XXX
 SG_ EBDFail : 5|1@0+(1,0)[0|1] "" Vector__XXX
 SG_ ESCActive_WGF040 : 3|1@0+(1,0)[0|1] "" Vector__XXX
 SG_ ESCDisable_WGF041 : 2|1@0+(1,0)[0|1] "" Vector__XXX
 SG_ ESCStatusLampReq : 14|2@0+(1,0)[0|3] "" Vector__XXX
 SG_ ESCWarningLamp_WG7048 : 9|1@0+(1,0)[0|1] "" Vector__XXX
 SG_ TCSActive_WGF042 : 8|1@0+(1,0)[0|1] "" Vector__XXX
 SG_ TCSFail : 22|1@0+(1,0)[0|1] "" Vector__XXX
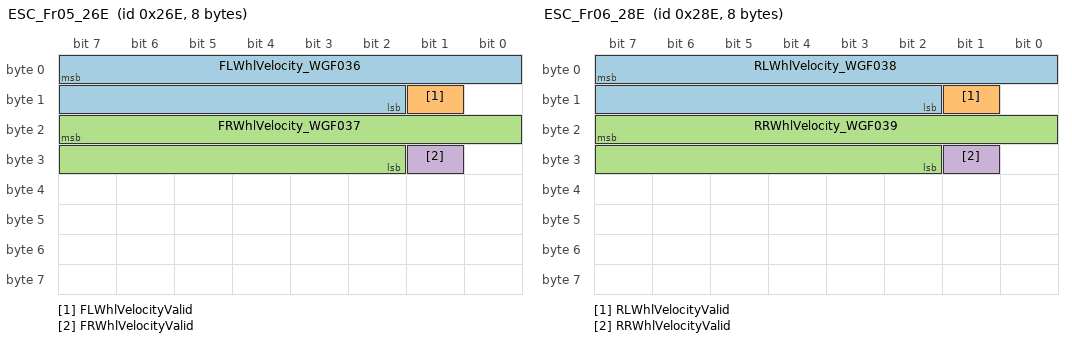
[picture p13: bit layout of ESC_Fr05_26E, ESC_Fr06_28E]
BO_ 622 ESC_Fr05_26E: 8 ESC
 SG_ FLWhlVelocity_WGF036 : 7|14@0+(0.03125,0)[0|511.9375] "km/h" Vector__XXX
 SG_ FLWhlVelocityValid : 9|1@0+(1,0)[0|1] "" Vector__XXX
 SG_ FRWhlVelocity_WGF037 : 23|14@0+(0.03125,0)[0|511.9375] "km/h" Vector__XXX
 SG_ FRWhlVelocityValid : 25|1@0+(1,0)[0|1] "" Vector__XXX
BO_ 654 ESC_Fr06_28E: 8 ESC
 SG_ RLWhlVelocity_WGF038 : 7|14@0+(0.03125,0)[0|511.9375] "km/h" Vector__XXX
 SG_ RLWhlVelocityValid : 9|1@0+(1,0)[0|1] "" Vector__XXX
 SG_ RRWhlVelocity_WGF039 : 23|14@0+(0.03125,0)[0|511.9375] "km/h" Vector__XXX
 SG_ RRWhlVelocityValid : 25|1@0+(1,0)[0|1] "" Vector__XXX
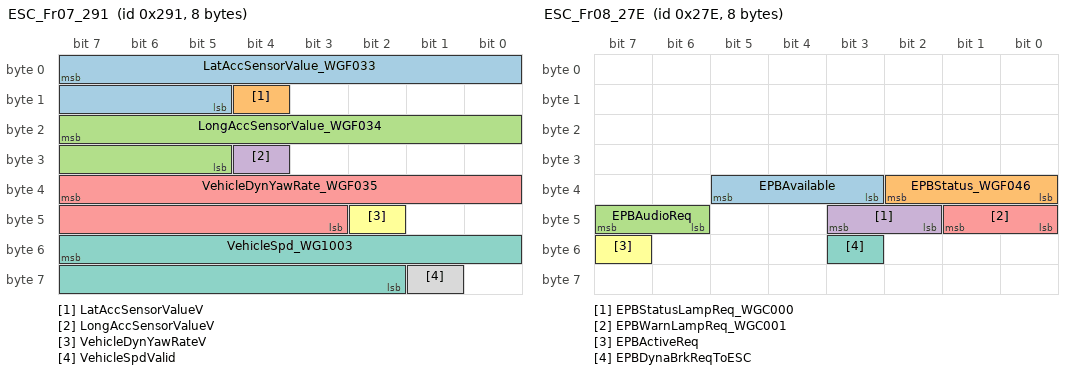
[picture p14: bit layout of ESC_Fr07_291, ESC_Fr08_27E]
BO_ 657 ESC_Fr07_291: 8 ESC
 SG_ LatAccSensorValue_WGF033 : 7|11@0+(0.01,-10.23)[-10.23|10.23] "m/s^2" Vector__XXX
 SG_ LatAccSensorValueV : 12|1@0+(1,0)[0|1] "" Vector__XXX
 SG_ LongAccSensorValue_WGF034 : 23|11@0+(0.01,-10.23)[-10.23|10.23] "m/s^2" Vector__XXX
 SG_ LongAccSensorValueV : 28|1@0+(1,0)[0|1] "" Vector__XXX
 SG_ VehicleDynYawRate_WGF035 : 39|13@0+(0.01,-40.95)[-40.95|40.95] "deg/sec" Vector__XXX
 SG_ VehicleDynYawRateV : 42|1@0+(1,0)[0|1] "" Vector__XXX
 SG_ VehicleSpd_WG1003 : 55|14@0+(0.03125,0)[0|511.9375] "km/h" Vector__XXX
 SG_ VehicleSpdValid : 57|1@0+(1,0)[0|1] "" Vector__XXX
BO_ 638 ESC_Fr08_27E: 8 ESC
 SG_ EPBAvailable : 37|3@0+(1,0)[0|7] "" Vector__XXX
 SG_ EPBStatus_WGF046 : 34|3@0+(1,0)[0|7] "" Vector__XXX
 SG_ EPBAudioReq : 47|2@0+(1,0)[0|3] "" Vector__XXX
 SG_ EPBStatusLampReq_WGC000 : 43|2@0+(1,0)[0|3] "" Vector__XXX
 SG_ EPBWarnLampReq_WGC001 : 41|2@0+(1,0)[0|3] "" Vector__XXX
 SG_ EPBActiveReq : 55|1@0+(1,0)[0|1] "" Vector__XXX
 SG_ EPBDynaBrkReqToESC : 51|1@0+(1,0)[0|1] "" Vector__XXX
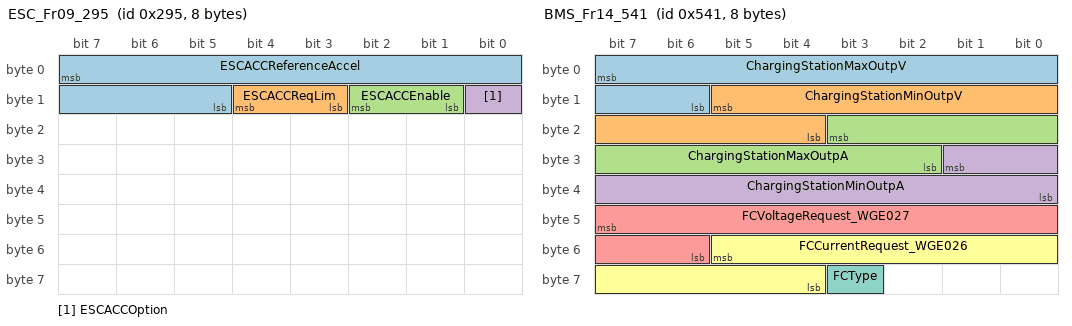
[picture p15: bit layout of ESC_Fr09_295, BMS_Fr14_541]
BO_ 661 ESC_Fr09_295: 8 ESC
 SG_ ESCACCReferenceAccel : 7|11@0+(0.01,-10.23)[-10.23|10.24] "m/s^2" Vector__XXX
 SG_ ESCACCReqLim : 12|2@0+(1,0)[0|3] "" Vector__XXX
 SG_ ESCACCEnable : 10|2@0+(1,0)[0|3] "" Vector__XXX
 SG_ ESCACCOption : 8|1@0+(1,0)[0|1] "" Vector__XXX
BO_ 1304 BMS_Fr12_518: 8 BMS
 SG_ BVOverTemp : 17|2@0+(1,0)[0|3] "" Vector__XXX
 SG_ IsolationFault_WG720B : 31|2@0+(1,0)[0|3] "" Vector__XXX
 SG_ BMSOverTempFault : 39|2@0+(1,0)[0|3] "" Vector__XXX
BO_ 1345 BMS_Fr14_541: 8 BMS
 SG_ ChargingStationMaxOutpV : 7|10@0+(1,0)[0|1000] "V" Vector__XXX
 SG_ ChargingStationMinOutpV : 13|10@0+(1,0)[0|1000] "V" Vector__XXX
 SG_ ChargingStationMaxOutpA : 19|10@0+(1,-400)[-400|400] "A" Vector__XXX
 SG_ ChargingStationMinOutpA : 25|10@0+(1,-400)[-400|400] "A" Vector__XXX
 SG_ FCVoltageRequest_WGE027 : 47|10@0+(1,0)[0|1000] "V" Vector__XXX
 SG_ FCCurrentRequest_WGE026 : 53|10@0+(1,-400)[-400|400] "A" Vector__XXX
 SG_ FCType : 59|1@0+(1,0)[0|1] "" Vector__XXX
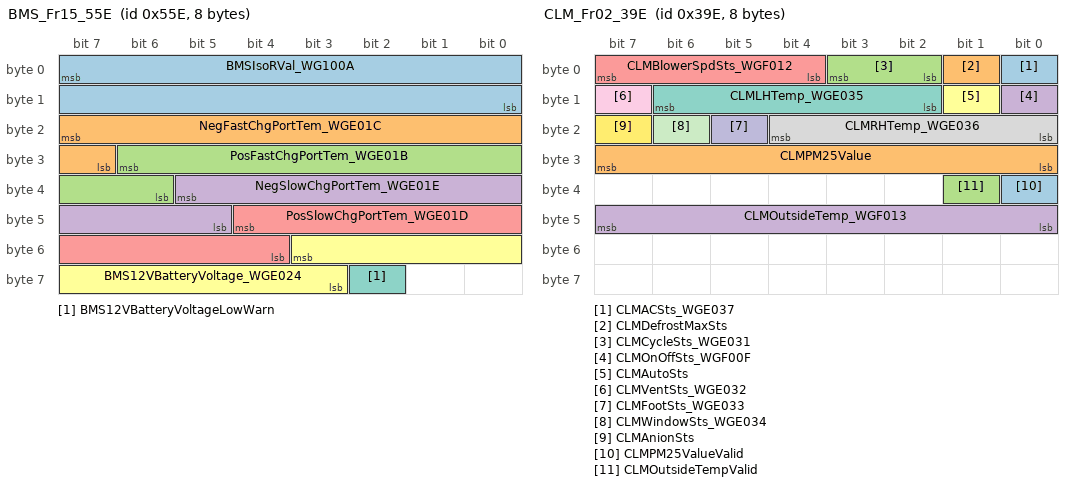
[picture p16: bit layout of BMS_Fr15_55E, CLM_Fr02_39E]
BO_ 1374 BMS_Fr15_55E: 8 BMS
 SG_ BMSIsoRVal_WG100A : 7|16@0+(1,0)[0|60000] "ΚΩ" Vector__XXX
 SG_ NegFastChgPortTem_WGE01C : 23|9@0+(1,-40)[-40|300] "℃" Vector__XXX
 SG_ PosFastChgPortTem_WGE01B : 30|9@0+(1,-40)[-40|300] "℃" Vector__XXX
 SG_ NegSlowChgPortTem_WGE01E : 37|9@0+(1,-40)[-40|300] "℃" Vector__XXX
 SG_ PosSlowChgPortTem_WGE01D : 44|9@0+(1,-40)[-40|300] "℃" Vector__XXX
 SG_ BMS12VBatteryVoltage_WGE024 : 51|9@0+(0.05,0)[0|25] "V" Vector__XXX
 SG_ BMS12VBatteryVoltageLowWarn : 58|1@0+(1,0)[0|1] "" Vector__XXX
BO_ 1952 DIAGPhysReqTBOX: 8 Tester
 SG_ DiagnosticReqTBOX : 7|64@0+(1,0)[0|0] "" Vector__XXX
BO_ 1968 DIAGPhysRespTBOX: 8 TBOX
 SG_ DiagnosticRespTBOX : 7|64@0+(1,0)[0|0] "" Vector__XXX
BO_ 2015 DIAG_FuncReq_7DF: 8 Tester
 SG_ DiagnosticFuncAddrReq : 7|64@0+(1,0)[0|0] "" Vector__XXX
BO_ 1013 IHU_Fr02_3F5: 8 IHU
 SG_ IHUChargeCmd : 33|1@0+(1,0)[0|1] "" Vector__XXX
 SG_ IHUChargeAppointmentSet : 32|1@0+(1,0)[0|1] "" Vector__XXX
 SG_ IHUChargeAppointmentTimeSet : 47|8@0+(10,0)[0|1440] "min" Vector__XXX
BO_ 1032 PLG_Fr01_408: 8 PLG
 SG_ PLGRearDoorStatus_WGF00E : 7|2@0+(1,0)[0|3] "" Vector__XXX
BO_ 853 PTC_Fr01_355: 8 PTC
 SG_ PTCPowerConsumption_WGE040 : 31|8@0+(0.1,0)[0|25.3] "kw" Vector__XXX
 SG_ PTCClntTempInlt_WGE041 : 47|8@0+(1,-40)[-40|100] "℃" Vector__XXX
 SG_ PTCClntTempOtlt_WGE042 : 55|8@0+(1,-40)[-40|100] "℃" Vector__XXX
 SG_ PTCWrkngSts_WGE038 : 7|2@0+(1,0)[0|3] "" Vector__XXX
BO_ 885 EAC_Fr01_375: 8 EACP
 SG_ EACACPSpeed_WGE03E : 31|7@0+(100,0)[0|8600] "rpm" Vector__XXX
 SG_ EACBaseState_WGE03C : 54|3@0+(1,0)[0|7] "" Vector__XXX
 SG_ EACInputVolt_WGE03F : 8|9@0+(1,0)[0|510] "v" Vector__XXX
BO_ 917 CLM_Fr01_395: 8 CLM
 SG_ CLMEACSpeedSet_WGE03D : 17|7@0+(100,0)[0|8600] "rpm" Vector__XXX
BO_ 926 CLM_Fr02_39E: 8 CLM
 SG_ CLMACSts_WGE037 : 0|1@0+(1,0)[0|1] "" Vector__XXX
 SG_ CLMDefrostMaxSts : 1|1@0+(1,0)[0|1] "" Vector__XXX
 SG_ CLMCycleSts_WGE031 : 3|2@0+(1,0)[0|3] "" Vector__XXX
 SG_ CLMOnOffSts_WGF00F : 8|1@0+(1,0)[0|1] "" Vector__XXX
 SG_ CLMBlowerSpdSts_WGF012 : 7|4@0+(1,0)[0|15] "" Vector__XXX
 SG_ CLMAutoSts : 9|1@0+(1,0)[0|1] "" Vector__XXX
 SG_ CLMLHTemp_WGE035 : 14|5@0+(0.5,16)[16|32] "" Vector__XXX
 SG_ CLMRHTemp_WGE036 : 20|5@0+(0.5,16)[16|32] "" Vector__XXX
 SG_ CLMVentSts_WGE032 : 15|1@0+(1,0)[0|1] "" Vector__XXX
 SG_ CLMFootSts_WGE033 : 21|1@0+(1,0)[0|1] "" Vector__XXX
 SG_ CLMWindowSts_WGE034 : 22|1@0+(1,0)[0|1] "" Vector__XXX
 SG_ CLMAnionSts : 23|1@0+(1,0)[0|1] "" Vector__XXX
 SG_ CLMPM25ValueValid : 32|1@0+(1,0)[0|1] "" Vector__XXX
 SG_ CLMPM25Value : 31|8@0+(4,0)[0|1020] "" Vector__XXX
 SG_ CLMOutsideTempValid : 33|1@0+(1,0)[0|1] "" Vector__XXX
 SG_ CLMOutsideTemp_WGF013 : 47|8@0+(0.5,-40)[-40|87.5] "℃" Vector__XXX
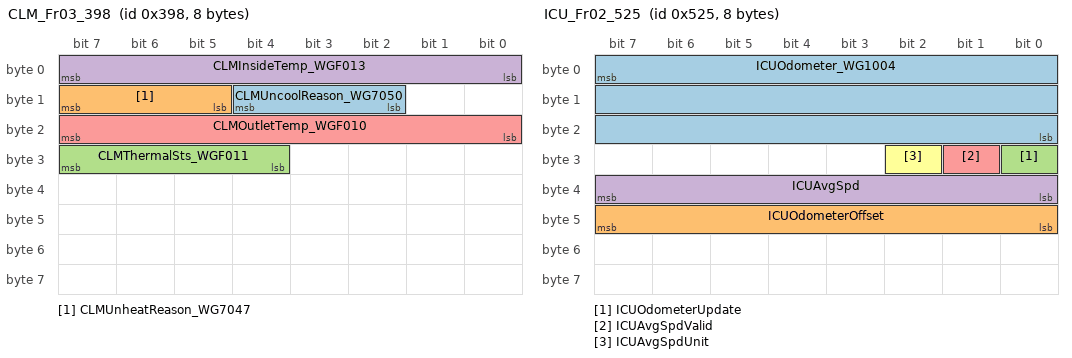
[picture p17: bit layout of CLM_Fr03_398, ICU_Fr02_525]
BO_ 920 CLM_Fr03_398: 8 CLM
 SG_ CLMUncoolReason_WG7050 : 12|3@0+(1,0)[0|7] "" Vector__XXX
 SG_ CLMUnheatReason_WG7047 : 15|3@0+(1,0)[0|7] "" Vector__XXX
 SG_ CLMThermalSts_WGF011 : 31|4@0+(1,0)[0|15] "" Vector__XXX
 SG_ CLMInsideTemp_WGF013 : 7|8@0+(0.5,-40)[-40|87.5] "" Vector__XXX
 SG_ CLMOutletTemp_WGF010 : 23|8@0+(0.5,-40)[-40|87.5] "" Vector__XXX
BO_ 542 ICU_Fr01_21E: 8 ICU
 SG_ ICUBrakeFluidLow_WG704A : 10|1@0+(1,0)[0|1] "" Vector__XXX
BO_ 1317 ICU_Fr02_525: 8 ICU
 SG_ ICUOdometer_WG1004 : 7|24@0+(0.1,0)[0|1677721.4] "km" Vector__XXX
 SG_ ICUOdometerOffset : 47|8@0+(1,0)[0|255] "km" Vector__XXX
 SG_ ICUOdometerUpdate : 24|1@0+(1,0)[0|1] "" Vector__XXX
 SG_ ICUAvgSpd : 39|8@0+(1,0)[0|255] "kph
mph" Vector__XXX
 SG_ ICUAvgSpdValid : 25|1@0+(1,0)[0|1] "" Vector__XXX
 SG_ ICUAvgSpdUnit : 26|1@0+(1,0)[0|1] "" Vector__XXX
BO_ 1318 TBOX_Fr05_526: 8 TBOX
 SG_ TBOXOdometer : 7|24@0+(0.1,0)[0|1677721.4] "km" Vector__XXX
BO_ 1319 BDM_Fr0B_527: 8 BDCM
 SG_ BDMOdometer : 7|24@0+(0.1,0)[0|1677721.4] "km" Vector__XXX
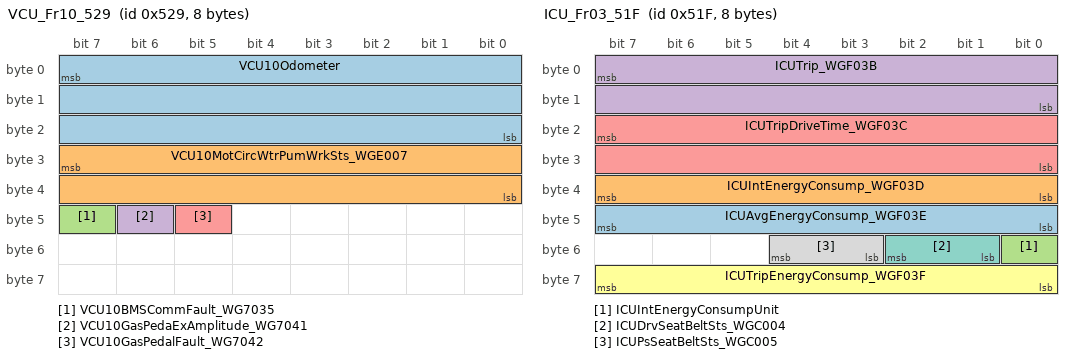
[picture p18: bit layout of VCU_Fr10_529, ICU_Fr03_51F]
BO_ 1321 VCU_Fr10_529: 8 VCU1
 SG_ VCU10Odometer : 7|24@0+(0.1,0)[0|1677721.4] "km" Vector__XXX
 SG_ VCU10MotCircWtrPumWrkSts_WGE007 : 31|16@0+(0.1,0)[0|100] "%" Vector__XXX
 SG_ VCU10BMSCommFault_WG7035 : 47|1@0+(1,0)[0|1] "" Vector__XXX
 SG_ VCU10GasPedaExAmplitude_WG7041 : 46|1@0+(1,0)[0|1] "" Vector__XXX
 SG_ VCU10GasPedalFault_WG7042 : 45|1@0+(1,0)[0|1] "" Vector__XXX
BO_ 1311 ICU_Fr03_51F: 8 ICU
 SG_ ICUAvgEnergyConsump_WGF03E : 47|8@0+(0.1,0)[0|25.5] "kwh/100km" Vector__XXX
 SG_ ICUIntEnergyConsump_WGF03D : 39|8@0+(0.1,0)[0|25.5] "kwh/100km
 kwh/h" Vector__XXX
 SG_ ICUIntEnergyConsumpUnit : 48|1@0+(1,0)[0|1] "" Vector__XXX
 SG_ ICUTrip_WGF03B : 7|16@0+(1,0)[0|65535] "km" Vector__XXX
 SG_ ICUTripDriveTime_WGF03C : 23|16@0+(1,0)[0|65535] "s" Vector__XXX
 SG_ ICUTripEnergyConsump_WGF03F : 63|8@0+(0.1,0)[0|25.5] "kwh/100km" Vector__XXX
 SG_ ICUDrvSeatBeltSts_WGC004 : 50|2@0+(1,0)[0|3] "" Vector__XXX
 SG_ ICUPsSeatBeltSts_WGC005 : 52|2@0+(1,0)[0|3] "" Vector__XXX
BO_ 1298 TAP_Fr01_512: 8 TAP
 SG_ TAPSystemStatus : 7|3@0+(1,0)[0|7] "" Vector__XXX
BO_ 1326 TAP_Fr02_52E: 8 TAP
 SG_ TapUpgradeResult : 2|3@0+(1,0)[0|7] "" Vector__XXX
BO_ 951 BMS_Fr17_3B7: 8 BMS
 SG_ BMS17CSIpValue : 7|32@0+(1,-2147483648)[0|1] "mA" Vector__XXX
 SG_ BMS17CSErrorIndication : 32|1@0+(1,0)[0|1] "" Vector__XXX
 SG_ BMS17CSErrorInformation : 39|7@0+(1,0)[0|127] "" Vector__XXX
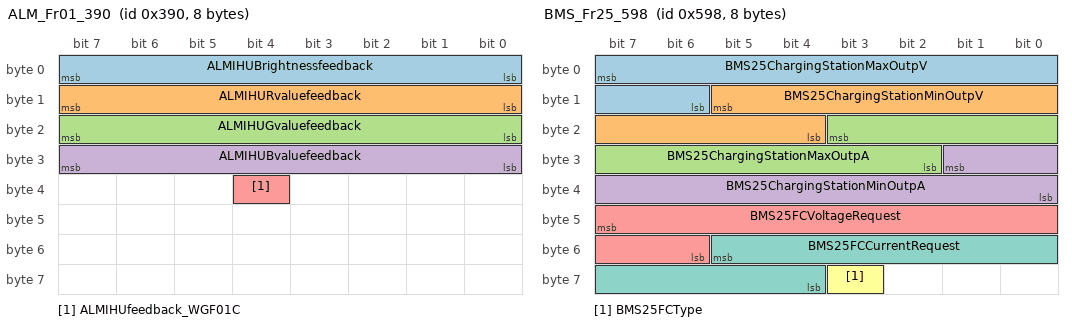
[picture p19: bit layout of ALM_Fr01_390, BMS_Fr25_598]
BO_ 912 ALM_Fr01_390: 8 ALM
 SG_ ALMIHUBrightnessfeedback : 7|8@0+(1,0)[0|100] "%" Vector__XXX
 SG_ ALMIHURvaluefeedback : 15|8@0+(1,0)[0|255] "" Vector__XXX
 SG_ ALMIHUGvaluefeedback : 23|8@0+(1,0)[0|255] "" Vector__XXX
 SG_ ALMIHUBvaluefeedback : 31|8@0+(1,0)[0|255] "" Vector__XXX
 SG_ ALMIHUfeedback_WGF01C : 36|1@0+(1,0)[0|1] "" Vector__XXX
BO_ 1430 BMS_Fr23_596: 8 BMS
 SG_ BMS58HdsahTotalCpSum_WGE022 : 39|25@0+(0.01,0)[0|210240] "Ah" Vector__XXX
BO_ 1431 BMS_Fr24_597: 8 BMS
 SG_ BMS24HdsahReActiveCpSum : 7|25@0+(0.01,0)[0|210240] "Ah" Vector__XXX
 SG_ BMS24HdsahActiveCpSum_WGE023 : 30|25@0+(0.01,0)[0|210240] "Ah" Vector__XXX
BO_ 1432 BMS_Fr25_598: 8 BMS
 SG_ BMS25ChargingStationMaxOutpV : 7|10@0+(1,0)[0|1000] "V" Vector__XXX
 SG_ BMS25ChargingStationMinOutpV : 13|10@0+(1,0)[0|1000] "V" Vector__XXX
 SG_ BMS25ChargingStationMaxOutpA : 19|10@0+(1,-400)[-400|400] "A" Vector__XXX
 SG_ BMS25ChargingStationMinOutpA : 25|10@0+(1,-400)[-400|400] "A" Vector__XXX
 SG_ BMS25FCVoltageRequest : 47|10@0+(1,0)[0|1000] "V" Vector__XXX
 SG_ BMS25FCType : 59|1@0+(1,0)[0|1] "/" Vector__XXX
 SG_ BMS25FCCurrentRequest : 53|10@0+(1,-400)[-400|400] "A" Vector__XXX
BO_ 1537 TBOXNM601: 8 TBOX
 SG_ TBOXSourceNodeIdentifier : 7|8@0+(1,0)[0|255] "" Vector__XXX
 SG_ TBOXRepeatMessageRequest : 8|1@0+(1,0)[0|1] "" Vector__XXX
 SG_ TBOXReserve1 : 11|3@0+(1,0)[0|3] "" Vector__XXX
 SG_ TBOXActiveWakeup : 12|1@0+(1,0)[0|1] "" Vector__XXX
 SG_ TBOXReserve2 : 15|3@0+(1,0)[0|7] "" Vector__XXX
 SG_ TBOXWakeUpReason1 : 16|1@0+(1,0)[0|1] "" Vector__XXX
 SG_ TBOXWakeUpReason2 : 17|1@0+(1,0)[0|1] "" Vector__XXX
 SG_ TBOXWakeUpReason3 : 18|1@0+(1,0)[0|1] "" Vector__XXX
 SG_ TBOXWakeUpReason4 : 19|1@0+(1,0)[0|1] "" Vector__XXX
 SG_ TBOXWakeUpReason5 : 20|1@0+(1,0)[0|1] "" Vector__XXX
 SG_ TBOXWakeUpReason6 : 21|1@0+(1,0)[0|1] "" Vector__XXX
 SG_ TBOXWakeUpReason7 : 22|1@0+(1,0)[0|1] "" Vector__XXX
 SG_ TBOXWakeUpReason8 : 23|1@0+(1,0)[0|1] "" Vector__XXX
 SG_ TBOXRepeatFromSleep : 24|1@0+(1,0)[0|1] "" Vector__XXX
 SG_ TBOXRepeatFromPrepare : 25|1@0+(1,0)[0|1] "" Vector__XXX
 SG_ TBOXRepeatFromNormal : 26|1@0+(1,0)[0|1] "" Vector__XXX
 SG_ TBOXRepeatFromReady : 27|1@0+(1,0)[0|1] "" Vector__XXX
 SG_ TBOXNormalFromRepeat : 28|1@0+(1,0)[0|1] "" Vector__XXX
 SG_ TBOXNormalFromReady : 29|1@0+(1,0)[0|1] "" Vector__XXX
 SG_ TBOXRemainNetworkWakeUpReason1 : 32|1@0+(1,0)[0|1] "" Vector__XXX
 SG_ TBOXRemainNetworkWakeUpReason2 : 33|1@0+(1,0)[0|1] "" Vector__XXX
 SG_ TBOXRemainNetworkWakeUpReason3 : 34|1@0+(1,0)[0|1] "" Vector__XXX
 SG_ TBOXRemainNetworkWakeUpReason4 : 35|1@0+(1,0)[0|1] "" Vector__XXX
 SG_ TBOXRemainNetworkWakeUpReason5 : 36|1@0+(1,0)[0|1] "" Vector__XXX
 SG_ TBOXRemainNetworkWakeUpReason6 : 37|1@0+(1,0)[0|1] "" Vector__XXX
 SG_ TBOXRemainNetworkWakeUpReason7 : 38|1@0+(1,0)[0|1] "" Vector__XXX
 SG_ TBOXRemainNetworkWakeUpReason8 : 39|1@0+(1,0)[0|1] "" Vector__XXX
 SG_ TBOXRemainNetworkWakeUpReason9 : 40|1@0+(1,0)[0|1] "" Vector__XXX
 SG_ TBOXRemainNetworkWakeUpReason10 : 41|1@0+(1,0)[0|1] "" Vector__XXX
 SG_ TBOXRemainNetworkWakeUpReason11 : 42|1@0+(1,0)[0|1] "" Vector__XXX
 SG_ TBOXRemainNetworkWakeUpReason12 : 43|1@0+(1,0)[0|1] "" Vector__XXX
 SG_ TBOXRemainNetworkWakeUpReason13 : 44|1@0+(1,0)[0|1] "" Vector__XXX
 SG_ TBOXRemainNetworkWakeUpReason14 : 45|1@0+(1,0)[0|1] "" Vector__XXX
 SG_ TBOXRemainNetworkWakeUpReason15 : 46|1@0+(1,0)[0|1] "" Vector__XXX
 SG_ TBOXRemainNetworkWakeUpReason16 : 47|1@0+(1,0)[0|1] "" Vector__XXX
 SG_ TBOXRemainNetworkWakeUpReason17 : 48|1@0+(1,0)[0|1] "" Vector__XXX
 SG_ TBOXRemainNetworkWakeUpReason18 : 49|1@0+(1,0)[0|1] "" Vector__XXX
 SG_ TBOXRemainNetworkWakeUpReason19 : 50|1@0+(1,0)[0|1] "" Vector__XXX
 SG_ TBOXRemainNetworkWakeUpReason20 : 51|1@0+(1,0)[0|1] "" Vector__XXX
 SG_ TBOXRemainNetworkWakeUpReason21 : 52|1@0+(1,0)[0|1] "" Vector__XXX
 SG_ TBOXRemainNetworkWakeUpReason22 : 53|1@0+(1,0)[0|1] "" Vector__XXX
 SG_ TBOXRemainNetworkWakeUpReason23 : 54|1@0+(1,0)[0|1] "" Vector__XXX
 SG_ TBOXRemainNetworkWakeUpReason24 : 55|1@0+(1,0)[0|1] "" Vector__XXX
 SG_ TBOXUserData5 : 63|8@0+(1,0)[0|255] "" Vector__XXX

BA_DEF_  "HSBaudrate" ENUM  "50000","100000","125000","250000","500000","1000000";
BA_DEF_ BO_  "VFrameFormat" ENUM  "StandardCAN","ExtendedCAN","reserved","J1939PG";

BA_ "HSBaudrate" 4;
BA_ "VFrameFormat" BO_ 563 0;
BA_ "VFrameFormat" BO_ 825 0;
BA_ "VFrameFormat" BO_ 601 0;
BA_ "VFrameFormat" BO_ 618 0;
BA_ "VFrameFormat" BO_ 906 0;
BA_ "VFrameFormat" BO_ 874 0;
BA_ "VFrameFormat" BO_ 225 0;
BA_ "VFrameFormat" BO_ 481 0;
BA_ "VFrameFormat" BO_ 872 0;
BA_ "VFrameFormat" BO_ 914 0;
BA_ "VFrameFormat" BO_ 858 0;
BA_ "VFrameFormat" BO_ 904 0;
BA_ "VFrameFormat" BO_ 646 0;
BA_ "VFrameFormat" BO_ 631 0;
BA_ "VFrameFormat" BO_ 1288 0;
BA_ "VFrameFormat" BO_ 1001 0;
BA_ "VFrameFormat" BO_ 666 0;
BA_ "VFrameFormat" BO_ 1291 0;
BA_ "VFrameFormat" BO_ 170 0;
BA_ "VFrameFormat" BO_ 187 0;
BA_ "VFrameFormat" BO_ 972 0;
BA_ "VFrameFormat" BO_ 1072 0;
BA_ "VFrameFormat" BO_ 200 0;
BA_ "VFrameFormat" BO_ 850 0;
BA_ "VFrameFormat" BO_ 1251 0;
BA_ "VFrameFormat" BO_ 1236 0;
BA_ "VFrameFormat" BO_ 426 0;
BA_ "VFrameFormat" BO_ 487 0;
BA_ "VFrameFormat" BO_ 1433 0;
BA_ "VFrameFormat" BO_ 1034 0;
BA_ "VFrameFormat" BO_ 1030 0;
BA_ "VFrameFormat" BO_ 778 0;
BA_ "VFrameFormat" BO_ 547 0;
BA_ "VFrameFormat" BO_ 1067 0;
BA_ "VFrameFormat" BO_ 1301 0;
BA_ "VFrameFormat" BO_ 1328 0;
BA_ "VFrameFormat" BO_ 1088 0;
BA_ "VFrameFormat" BO_ 1093 0;
BA_ "VFrameFormat" BO_ 454 0;
BA_ "VFrameFormat" BO_ 456 0;
BA_ "VFrameFormat" BO_ 229 0;
BA_ "VFrameFormat" BO_ 622 0;
BA_ "VFrameFormat" BO_ 654 0;
BA_ "VFrameFormat" BO_ 657 0;
BA_ "VFrameFormat" BO_ 638 0;
BA_ "VFrameFormat" BO_ 661 0;
BA_ "VFrameFormat" BO_ 1304 0;
BA_ "VFrameFormat" BO_ 1345 0;
BA_ "VFrameFormat" BO_ 1374 0;
BA_ "VFrameFormat" BO_ 1952 0;
BA_ "VFrameFormat" BO_ 1968 0;
BA_ "VFrameFormat" BO_ 2015 0;
BA_ "VFrameFormat" BO_ 1013 0;
BA_ "VFrameFormat" BO_ 1032 0;
BA_ "VFrameFormat" BO_ 853 0;
BA_ "VFrameFormat" BO_ 885 0;
BA_ "VFrameFormat" BO_ 917 0;
BA_ "VFrameFormat" BO_ 926 0;
BA_ "VFrameFormat" BO_ 920 0;
BA_ "VFrameFormat" BO_ 542 0;
BA_ "VFrameFormat" BO_ 1317 0;
BA_ "VFrameFormat" BO_ 1318 0;
BA_ "VFrameFormat" BO_ 1319 0;
BA_ "VFrameFormat" BO_ 1321 0;
BA_ "VFrameFormat" BO_ 1311 0;
BA_ "VFrameFormat" BO_ 1298 0;
BA_ "VFrameFormat" BO_ 1326 0;
BA_ "VFrameFormat" BO_ 951 0;
BA_ "VFrameFormat" BO_ 912 0;
BA_ "VFrameFormat" BO_ 1430 0;
BA_ "VFrameFormat" BO_ 1431 0;
BA_ "VFrameFormat" BO_ 1432 0;
BA_ "VFrameFormat" BO_ 1537 0;

BA_ "IN_VEHITYPE" 01;
BA_ "IN_VEHISTATE_00" 02
BA_ "IN_VEHISTATE_01" 03
BA_ "IN_VEHISTATE_02" 01
BA_ "IN_VEHISTATE_03" 03

BA_ "IN_CHGSTATE_00"  03
BA_ "IN_CHGSTATE_01"  01
BA_ "IN_CHGSTATE_02"  02
BA_ "IN_CHGSTATE_03"  04

BA_ "IN_DCDCSTATE_00" 02
BA_ "IN_DCDCSTATE_01" 01
BA_ "IN_DCDCSTATE_02" FE

BA_ "IN_SHIFT_05" N
BA_ "IN_SHIFT_06" N
BA_ "IN_SHIFT_08" S
BA_ "IN_SHIFT_0A" P
BA_ "IN_SHIFT_0B" D
BA_ "IN_SHIFT_0C" N
BA_ "IN_SHIFT_0D" R
BA_ "IN_SHIFT_0E" P
BA_ "IN_SHIFT_0F" FF
